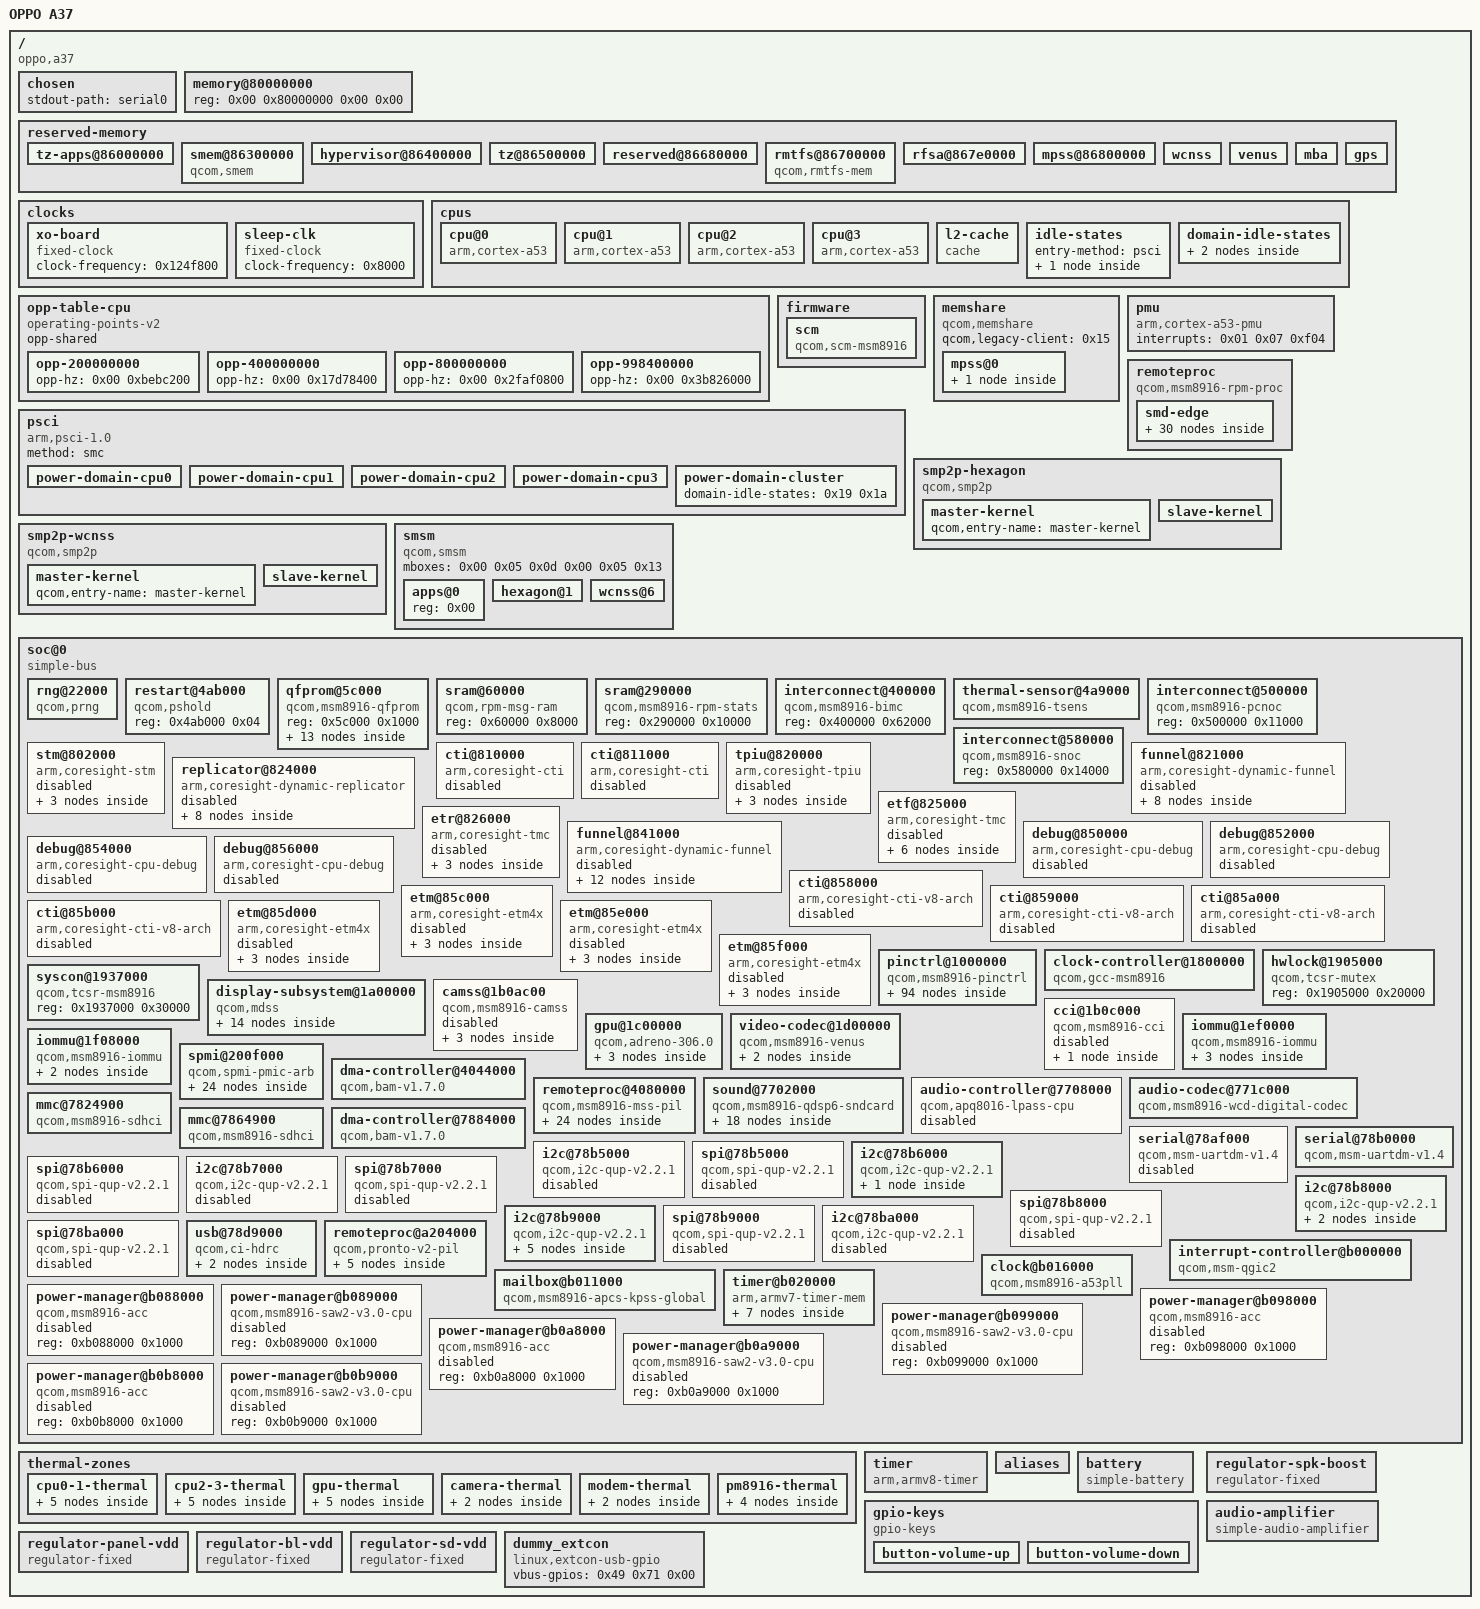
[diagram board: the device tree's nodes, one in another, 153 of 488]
/dts-v1/;

/ {
	interrupt-parent = <0x01>;
	#address-cells = <0x02>;
	#size-cells = <0x02>;
	model = "OPPO A37";
	compatible = "oppo,a37", "qcom,msm8916";
	chassis-type = "handset";

	chosen {
		stdout-path = "serial0";
	};

	memory@80000000 {
		device_type = "memory";
		reg = <0x00 0x80000000 0x00 0x00>;
	};

	reserved-memory {
		#address-cells = <0x02>;
		#size-cells = <0x02>;
		ranges;

		tz-apps@86000000 {
			reg = <0x00 0x86000000 0x00 0x300000>;
			no-map;
		};

		smem@86300000 {
			compatible = "qcom,smem";
			reg = <0x00 0x86300000 0x00 0x100000>;
			no-map;
			hwlocks = <0x02 0x03>;
			qcom,rpm-msg-ram = <0x03>;
		};

		hypervisor@86400000 {
			reg = <0x00 0x86400000 0x00 0x100000>;
			no-map;
		};

		tz@86500000 {
			reg = <0x00 0x86500000 0x00 0x180000>;
			no-map;
		};

		reserved@86680000 {
			reg = <0x00 0x86680000 0x00 0x80000>;
			no-map;
		};

		rmtfs@86700000 {
			compatible = "qcom,rmtfs-mem";
			reg = <0x00 0x86700000 0x00 0xe0000>;
			no-map;
			qcom,client-id = <0x01>;
		};

		rfsa@867e0000 {
			reg = <0x00 0x867e0000 0x00 0x20000>;
			no-map;
		};

		mpss@86800000 {
			reg = <0x00 0x86800000 0x00 0x5500000>;
			no-map;
			status = "okay";
			phandle = <0x6a>;
		};

		wcnss {
			size = <0x00 0x600000>;
			alignment = <0x00 0x100000>;
			alloc-ranges = <0x00 0x86800000 0x00 0x8000000>;
			no-map;
			status = "okay";
			phandle = <0xa2>;
		};

		venus {
			size = <0x00 0x500000>;
			alignment = <0x00 0x100000>;
			alloc-ranges = <0x00 0x86800000 0x00 0x8000000>;
			no-map;
			status = "okay";
			phandle = <0x5b>;
		};

		mba {
			size = <0x00 0x100000>;
			alignment = <0x00 0x100000>;
			alloc-ranges = <0x00 0x86800000 0x00 0x8000000>;
			no-map;
			status = "okay";
			phandle = <0x69>;
		};

		gps {
			size = <0x00 0x200000>;
			alignment = <0x00 0x100000>;
			alloc-ranges = <0x00 0x86800000 0x00 0x8000000>;
			no-map;
			status = "okay";
			phandle = <0x16>;
		};
	};

	clocks {

		xo-board {
			compatible = "fixed-clock";
			#clock-cells = <0x00>;
			clock-frequency = <0x124f800>;
			phandle = <0x1b>;
		};

		sleep-clk {
			compatible = "fixed-clock";
			#clock-cells = <0x00>;
			clock-frequency = <0x8000>;
			phandle = <0x4a>;
		};
	};

	cpus {
		#address-cells = <0x01>;
		#size-cells = <0x00>;

		cpu@0 {
			device_type = "cpu";
			compatible = "arm,cortex-a53";
			reg = <0x00>;
			next-level-cache = <0x04>;
			enable-method = "psci";
			clocks = <0x05>;
			operating-points-v2 = <0x06>;
			#cooling-cells = <0x02>;
			power-domains = <0x07>;
			power-domain-names = "psci";
			qcom,acc = <0x08>;
			qcom,saw = <0x09>;
			phandle = <0x3d>;
		};

		cpu@1 {
			device_type = "cpu";
			compatible = "arm,cortex-a53";
			reg = <0x01>;
			next-level-cache = <0x04>;
			enable-method = "psci";
			clocks = <0x05>;
			operating-points-v2 = <0x06>;
			#cooling-cells = <0x02>;
			power-domains = <0x0a>;
			power-domain-names = "psci";
			qcom,acc = <0x0b>;
			qcom,saw = <0x0c>;
			phandle = <0x3e>;
		};

		cpu@2 {
			device_type = "cpu";
			compatible = "arm,cortex-a53";
			reg = <0x02>;
			next-level-cache = <0x04>;
			enable-method = "psci";
			clocks = <0x05>;
			operating-points-v2 = <0x06>;
			#cooling-cells = <0x02>;
			power-domains = <0x0d>;
			power-domain-names = "psci";
			qcom,acc = <0x0e>;
			qcom,saw = <0x0f>;
			phandle = <0x3f>;
		};

		cpu@3 {
			device_type = "cpu";
			compatible = "arm,cortex-a53";
			reg = <0x03>;
			next-level-cache = <0x04>;
			enable-method = "psci";
			clocks = <0x05>;
			operating-points-v2 = <0x06>;
			#cooling-cells = <0x02>;
			power-domains = <0x10>;
			power-domain-names = "psci";
			qcom,acc = <0x11>;
			qcom,saw = <0x12>;
			phandle = <0x40>;
		};

		l2-cache {
			compatible = "cache";
			cache-level = <0x02>;
			cache-unified;
			phandle = <0x04>;
		};

		idle-states {
			entry-method = "psci";

			cpu-sleep-0 {
				compatible = "arm,idle-state";
				idle-state-name = "standalone-power-collapse";
				arm,psci-suspend-param = <0x40000002>;
				entry-latency-us = <0x82>;
				exit-latency-us = <0x96>;
				min-residency-us = <0x7d0>;
				local-timer-stop;
				phandle = <0x18>;
			};
		};

		domain-idle-states {

			cluster-retention {
				compatible = "domain-idle-state";
				arm,psci-suspend-param = <0x41000012>;
				entry-latency-us = <0x1f4>;
				exit-latency-us = <0x1f4>;
				min-residency-us = <0x7d0>;
				phandle = <0x19>;
			};

			cluster-gdhs {
				compatible = "domain-idle-state";
				arm,psci-suspend-param = <0x41000032>;
				entry-latency-us = <0x7d0>;
				exit-latency-us = <0x7d0>;
				min-residency-us = <0x1770>;
				phandle = <0x1a>;
			};
		};
	};

	opp-table-cpu {
		compatible = "operating-points-v2";
		opp-shared;
		phandle = <0x06>;

		opp-200000000 {
			opp-hz = <0x00 0xbebc200>;
		};

		opp-400000000 {
			opp-hz = <0x00 0x17d78400>;
		};

		opp-800000000 {
			opp-hz = <0x00 0x2faf0800>;
		};

		opp-998400000 {
			opp-hz = <0x00 0x3b826000>;
		};
	};

	firmware {

		scm {
			compatible = "qcom,scm-msm8916", "qcom,scm";
			clocks = <0x13 0x68 0x13 0x67 0x13 0x66>;
			clock-names = "core", "bus", "iface";
			#reset-cells = <0x01>;
			qcom,dload-mode = <0x14 0x6100>;
			phandle = <0x67>;
		};
	};

	memshare {
		compatible = "qcom,memshare";
		qcom,legacy-client = <0x15>;
		status = "okay";
		#address-cells = <0x01>;
		#size-cells = <0x00>;

		mpss@0 {
			reg = <0x00>;
			qcom,qrtr-node = <0x00>;
			#address-cells = <0x01>;
			#size-cells = <0x00>;

			gps@0 {
				reg = <0x00>;
				memory-region = <0x16>;
				phandle = <0x15>;
			};
		};
	};

	pmu {
		compatible = "arm,cortex-a53-pmu";
		interrupts = <0x01 0x07 0xf04>;
	};

	psci {
		compatible = "arm,psci-1.0";
		method = "smc";

		power-domain-cpu0 {
			#power-domain-cells = <0x00>;
			power-domains = <0x17>;
			domain-idle-states = <0x18>;
			phandle = <0x07>;
		};

		power-domain-cpu1 {
			#power-domain-cells = <0x00>;
			power-domains = <0x17>;
			domain-idle-states = <0x18>;
			phandle = <0x0a>;
		};

		power-domain-cpu2 {
			#power-domain-cells = <0x00>;
			power-domains = <0x17>;
			domain-idle-states = <0x18>;
			phandle = <0x0d>;
		};

		power-domain-cpu3 {
			#power-domain-cells = <0x00>;
			power-domains = <0x17>;
			domain-idle-states = <0x18>;
			phandle = <0x10>;
		};

		power-domain-cluster {
			#power-domain-cells = <0x00>;
			domain-idle-states = <0x19 0x1a>;
			phandle = <0x17>;
		};
	};

	remoteproc {
		compatible = "qcom,msm8916-rpm-proc", "qcom,rpm-proc";

		smd-edge {
			interrupts = <0x00 0xa8 0x01>;
			mboxes = <0x05 0x00>;
			qcom,smd-edge = <0x0f>;

			rpm-requests {
				compatible = "qcom,rpm-msm8916", "qcom,smd-rpm";
				qcom,smd-channels = "rpm_requests";

				clock-controller {
					compatible = "qcom,rpmcc-msm8916", "qcom,rpmcc";
					#clock-cells = <0x01>;
					clocks = <0x1b>;
					clock-names = "xo";
					phandle = <0x2c>;
				};

				power-controller {
					compatible = "qcom,msm8916-rpmpd";
					#power-domain-cells = <0x01>;
					operating-points-v2 = <0x1c>;
					phandle = <0x65>;

					opp-table {
						compatible = "operating-points-v2";
						phandle = <0x1c>;

						opp1 {
							opp-level = <0x01>;
						};

						opp2 {
							opp-level = <0x02>;
						};

						opp3 {
							opp-level = <0x03>;
						};

						opp4 {
							opp-level = <0x04>;
						};

						opp5 {
							opp-level = <0x05>;
						};

						opp6 {
							opp-level = <0x06>;
						};
					};
				};

				regulators {
					compatible = "qcom,rpm-pm8916-regulators";
					vdd_l1_l2_l3-supply = <0x1d>;
					vdd_l4_l5_l6-supply = <0x1e>;
					vdd_l7-supply = <0x1e>;

					s3 {
						regulator-min-microvolt = <0x1312d0>;
						regulator-max-microvolt = <0x149970>;
						regulator-always-on;
						phandle = <0x1d>;
					};

					s4 {
						regulator-min-microvolt = <0x1c3a90>;
						regulator-max-microvolt = <0x20ce70>;
						regulator-always-on;
						phandle = <0x1e>;
					};

					l1 {
					};

					l2 {
						regulator-min-microvolt = <0x124f80>;
						regulator-max-microvolt = <0x124f80>;
						regulator-always-on;
						phandle = <0x4f>;
					};

					l4 {
					};

					l5 {
						regulator-min-microvolt = <0x1b7740>;
						regulator-max-microvolt = <0x1b7740>;
						regulator-always-on;
						phandle = <0x62>;
					};

					l6 {
						regulator-min-microvolt = <0x1b7740>;
						regulator-max-microvolt = <0x1b7740>;
						phandle = <0x50>;
					};

					l7 {
						regulator-min-microvolt = <0x1b7740>;
						regulator-max-microvolt = <0x1b7740>;
						regulator-always-on;
						phandle = <0x68>;
					};

					l8 {
						regulator-min-microvolt = <0x1b7740>;
						regulator-max-microvolt = <0x2d0370>;
						regulator-always-on;
						regulator-boot-on;
						phandle = <0x78>;
					};

					l9 {
						regulator-min-microvolt = <0x325aa0>;
						regulator-max-microvolt = <0x325aa0>;
						regulator-always-on;
						regulator-boot-on;
						phandle = <0xa6>;
					};

					l10 {
					};

					l11 {
						regulator-min-microvolt = <0x2d0370>;
						regulator-max-microvolt = <0x2d0370>;
						regulator-allow-set-load;
						regulator-system-load = <0x30d40>;
					};

					l12 {
						regulator-min-microvolt = <0x1b7740>;
						regulator-max-microvolt = <0x2d0370>;
						phandle = <0x7d>;
					};

					l13 {
						regulator-min-microvolt = <0x2eebb8>;
						regulator-max-microvolt = <0x2eebb8>;
						phandle = <0x63>;
					};

					l14 {
						regulator-min-microvolt = <0x1b7740>;
						regulator-max-microvolt = <0x2d0370>;
						regulator-always-on;
						regulator-boot-on;
					};

					l15 {
						regulator-min-microvolt = <0x1b7740>;
						regulator-max-microvolt = <0x2d0370>;
						regulator-always-on;
						regulator-boot-on;
					};

					l16 {
					};

					l17 {
						regulator-min-microvolt = <0x2b7cd0>;
						regulator-max-microvolt = <0x2b7cd0>;
						phandle = <0x89>;
					};

					l18 {
					};
				};
			};
		};
	};

	smp2p-hexagon {
		compatible = "qcom,smp2p";
		qcom,smem = <0x1b3 0x1ac>;
		interrupts = <0x00 0x1b 0x01>;
		mboxes = <0x05 0x0e>;
		qcom,local-pid = <0x00>;
		qcom,remote-pid = <0x01>;

		master-kernel {
			qcom,entry-name = "master-kernel";
			#qcom,smem-state-cells = <0x01>;
			phandle = <0x66>;
		};

		slave-kernel {
			qcom,entry-name = "slave-kernel";
			interrupt-controller;
			#interrupt-cells = <0x02>;
			phandle = <0x64>;
		};
	};

	smp2p-wcnss {
		compatible = "qcom,smp2p";
		qcom,smem = <0x1c3 0x1af>;
		interrupts = <0x00 0x8f 0x01>;
		mboxes = <0x05 0x12>;
		qcom,local-pid = <0x00>;
		qcom,remote-pid = <0x04>;

		master-kernel {
			qcom,entry-name = "master-kernel";
			#qcom,smem-state-cells = <0x01>;
			phandle = <0xa4>;
		};

		slave-kernel {
			qcom,entry-name = "slave-kernel";
			interrupt-controller;
			#interrupt-cells = <0x02>;
			phandle = <0xa3>;
		};
	};

	smsm {
		compatible = "qcom,smsm";
		#address-cells = <0x01>;
		#size-cells = <0x00>;
		mboxes = <0x00 0x05 0x0d 0x00 0x05 0x13>;

		apps@0 {
			reg = <0x00>;
			#qcom,smem-state-cells = <0x01>;
			phandle = <0x6c>;
		};

		hexagon@1 {
			reg = <0x01>;
			interrupts = <0x00 0x1a 0x01>;
			interrupt-controller;
			#interrupt-cells = <0x02>;
			phandle = <0x6b>;
		};

		wcnss@6 {
			reg = <0x06>;
			interrupts = <0x00 0x90 0x01>;
			interrupt-controller;
			#interrupt-cells = <0x02>;
		};
	};

	soc@0 {
		#address-cells = <0x01>;
		#size-cells = <0x01>;
		ranges = <0x00 0x00 0x00 0xffffffff>;
		compatible = "simple-bus";

		rng@22000 {
			compatible = "qcom,prng";
			reg = <0x22000 0x200>;
			clocks = <0x13 0x79>;
			clock-names = "core";
		};

		restart@4ab000 {
			compatible = "qcom,pshold";
			reg = <0x4ab000 0x04>;
		};

		qfprom@5c000 {
			compatible = "qcom,msm8916-qfprom", "qcom,qfprom";
			reg = <0x5c000 0x1000>;
			#address-cells = <0x01>;
			#size-cells = <0x01>;

			base1@d0 {
				reg = <0xd0 0x01>;
				bits = <0x00 0x07>;
				phandle = <0x20>;
			};

			s0-p1@d0 {
				reg = <0xd0 0x02>;
				bits = <0x07 0x05>;
				phandle = <0x22>;
			};

			s0-p2@d1 {
				reg = <0xd1 0x02>;
				bits = <0x04 0x05>;
				phandle = <0x23>;
			};

			s1-p1@d2 {
				reg = <0xd2 0x01>;
				bits = <0x01 0x05>;
				phandle = <0x24>;
			};

			s1-p2@d2 {
				reg = <0xd2 0x02>;
				bits = <0x06 0x05>;
				phandle = <0x25>;
			};

			s2-p1@d3 {
				reg = <0xd3 0x01>;
				bits = <0x03 0x05>;
				phandle = <0x26>;
			};

			s2-p2@d4 {
				reg = <0xd4 0x01>;
				bits = <0x00 0x05>;
				phandle = <0x27>;
			};

			s4-p1@d4 {
				reg = <0xd4 0x02>;
				bits = <0x05 0x05>;
				phandle = <0x28>;
			};

			s4-p2@d5 {
				reg = <0xd5 0x01>;
				bits = <0x02 0x05>;
				phandle = <0x29>;
			};

			s5-p1@d5 {
				reg = <0xd5 0x02>;
				bits = <0x07 0x05>;
				phandle = <0x2a>;
			};

			s5-p2@d6 {
				reg = <0xd6 0x02>;
				bits = <0x04 0x05>;
				phandle = <0x2b>;
			};

			base2@d7 {
				reg = <0xd7 0x01>;
				bits = <0x01 0x07>;
				phandle = <0x21>;
			};

			mode@ef {
				reg = <0xef 0x01>;
				bits = <0x05 0x03>;
				phandle = <0x1f>;
			};
		};

		sram@60000 {
			compatible = "qcom,rpm-msg-ram";
			reg = <0x60000 0x8000>;
			phandle = <0x03>;
		};

		sram@290000 {
			compatible = "qcom,msm8916-rpm-stats";
			reg = <0x290000 0x10000>;
		};

		interconnect@400000 {
			compatible = "qcom,msm8916-bimc";
			reg = <0x400000 0x62000>;
			#interconnect-cells = <0x01>;
		};

		thermal-sensor@4a9000 {
			compatible = "qcom,msm8916-tsens", "qcom,tsens-v0_1";
			reg = <0x4a9000 0x1000 0x4a8000 0x1000>;
			nvmem-cells = <0x1f 0x20 0x21 0x22 0x23 0x24 0x25 0x26 0x27 0x28 0x29 0x2a 0x2b>;
			nvmem-cell-names = "mode", "base1", "base2", "s0_p1", "s0_p2", "s1_p1", "s1_p2", "s2_p1", "s2_p2", "s4_p1", "s4_p2", "s5_p1", "s5_p2";
			#qcom,sensors = <0x05>;
			interrupts = <0x00 0xb8 0x04>;
			interrupt-names = "uplow";
			#thermal-sensor-cells = <0x01>;
			phandle = <0xa9>;
		};

		interconnect@500000 {
			compatible = "qcom,msm8916-pcnoc";
			reg = <0x500000 0x11000>;
			#interconnect-cells = <0x01>;
		};

		interconnect@580000 {
			compatible = "qcom,msm8916-snoc";
			reg = <0x580000 0x14000>;
			#interconnect-cells = <0x01>;
		};

		stm@802000 {
			compatible = "arm,coresight-stm", "arm,primecell";
			reg = <0x802000 0x1000 0x9280000 0x180000>;
			reg-names = "stm-base", "stm-stimulus-base";
			clocks = <0x2c 0x08 0x2c 0x09>;
			clock-names = "apb_pclk", "atclk";
			status = "disabled";

			out-ports {

				port {

					endpoint {
						remote-endpoint = <0x2d>;
						phandle = <0x30>;
					};
				};
			};
		};

		cti@810000 {
			compatible = "arm,coresight-cti", "arm,primecell";
			reg = <0x810000 0x1000>;
			clocks = <0x2c 0x08>;
			clock-names = "apb_pclk";
			status = "disabled";
		};

		cti@811000 {
			compatible = "arm,coresight-cti", "arm,primecell";
			reg = <0x811000 0x1000>;
			clocks = <0x2c 0x08>;
			clock-names = "apb_pclk";
			status = "disabled";
		};

		tpiu@820000 {
			compatible = "arm,coresight-tpiu", "arm,primecell";
			reg = <0x820000 0x1000>;
			clocks = <0x2c 0x08 0x2c 0x09>;
			clock-names = "apb_pclk", "atclk";
			status = "disabled";

			in-ports {

				port {

					endpoint {
						remote-endpoint = <0x2e>;
						phandle = <0x33>;
					};
				};
			};
		};

		funnel@821000 {
			compatible = "arm,coresight-dynamic-funnel", "arm,primecell";
			reg = <0x821000 0x1000>;
			clocks = <0x2c 0x08 0x2c 0x09>;
			clock-names = "apb_pclk", "atclk";
			status = "disabled";

			in-ports {
				#address-cells = <0x01>;
				#size-cells = <0x00>;

				port@4 {
					reg = <0x04>;

					endpoint {
						remote-endpoint = <0x2f>;
						phandle = <0x3c>;
					};
				};

				port@7 {
					reg = <0x07>;

					endpoint {
						remote-endpoint = <0x30>;
						phandle = <0x2d>;
					};
				};
			};

			out-ports {

				port {

					endpoint {
						remote-endpoint = <0x31>;
						phandle = <0x35>;
					};
				};
			};
		};

		replicator@824000 {
			compatible = "arm,coresight-dynamic-replicator", "arm,primecell";
			reg = <0x824000 0x1000>;
			clocks = <0x2c 0x08 0x2c 0x09>;
			clock-names = "apb_pclk", "atclk";
			status = "disabled";

			out-ports {
				#address-cells = <0x01>;
				#size-cells = <0x00>;

				port@0 {
					reg = <0x00>;

					endpoint {
						remote-endpoint = <0x32>;
						phandle = <0x37>;
					};
				};

				port@1 {
					reg = <0x01>;

					endpoint {
						remote-endpoint = <0x33>;
						phandle = <0x2e>;
					};
				};
			};

			in-ports {

				port {

					endpoint {
						remote-endpoint = <0x34>;
						phandle = <0x36>;
					};
				};
			};
		};

		etf@825000 {
			compatible = "arm,coresight-tmc", "arm,primecell";
			reg = <0x825000 0x1000>;
			clocks = <0x2c 0x08 0x2c 0x09>;
			clock-names = "apb_pclk", "atclk";
			status = "disabled";

			in-ports {

				port {

					endpoint {
						remote-endpoint = <0x35>;
						phandle = <0x31>;
					};
				};
			};

			out-ports {

				port {

					endpoint {
						remote-endpoint = <0x36>;
						phandle = <0x34>;
					};
				};
			};
		};

		etr@826000 {
			compatible = "arm,coresight-tmc", "arm,primecell";
			reg = <0x826000 0x1000>;
			clocks = <0x2c 0x08 0x2c 0x09>;
			clock-names = "apb_pclk", "atclk";
			status = "disabled";

			in-ports {

				port {

					endpoint {
						remote-endpoint = <0x37>;
						phandle = <0x32>;
					};
				};
			};
		};

		funnel@841000 {
			compatible = "arm,coresight-dynamic-funnel", "arm,primecell";
			reg = <0x841000 0x1000>;
			clocks = <0x2c 0x08 0x2c 0x09>;
			clock-names = "apb_pclk", "atclk";
			status = "disabled";

			in-ports {
				#address-cells = <0x01>;
				#size-cells = <0x00>;

				port@0 {
					reg = <0x00>;

					endpoint {
						remote-endpoint = <0x38>;
						phandle = <0x45>;
					};
				};

				port@1 {
					reg = <0x01>;

					endpoint {
						remote-endpoint = <0x39>;
						phandle = <0x46>;
					};
				};

				port@2 {
					reg = <0x02>;

					endpoint {
						remote-endpoint = <0x3a>;
						phandle = <0x47>;
					};
				};

				port@3 {
					reg = <0x03>;

					endpoint {
						remote-endpoint = <0x3b>;
						phandle = <0x48>;
					};
				};
			};

			out-ports {

				port {

					endpoint {
						remote-endpoint = <0x3c>;
						phandle = <0x2f>;
					};
				};
			};
		};

		debug@850000 {
			compatible = "arm,coresight-cpu-debug", "arm,primecell";
			reg = <0x850000 0x1000>;
			clocks = <0x2c 0x08>;
			clock-names = "apb_pclk";
			cpu = <0x3d>;
			status = "disabled";
		};

		debug@852000 {
			compatible = "arm,coresight-cpu-debug", "arm,primecell";
			reg = <0x852000 0x1000>;
			clocks = <0x2c 0x08>;
			clock-names = "apb_pclk";
			cpu = <0x3e>;
			status = "disabled";
		};

		debug@854000 {
			compatible = "arm,coresight-cpu-debug", "arm,primecell";
			reg = <0x854000 0x1000>;
			clocks = <0x2c 0x08>;
			clock-names = "apb_pclk";
			cpu = <0x3f>;
			status = "disabled";
		};

		debug@856000 {
			compatible = "arm,coresight-cpu-debug", "arm,primecell";
			reg = <0x856000 0x1000>;
			clocks = <0x2c 0x08>;
			clock-names = "apb_pclk";
			cpu = <0x40>;
			status = "disabled";
		};

		cti@858000 {
			compatible = "arm,coresight-cti-v8-arch", "arm,coresight-cti", "arm,primecell";
			reg = <0x858000 0x1000>;
			clocks = <0x2c 0x08>;
			clock-names = "apb_pclk";
			cpu = <0x3d>;
			arm,cs-dev-assoc = <0x41>;
			status = "disabled";
		};

		cti@859000 {
			compatible = "arm,coresight-cti-v8-arch", "arm,coresight-cti", "arm,primecell";
			reg = <0x859000 0x1000>;
			clocks = <0x2c 0x08>;
			clock-names = "apb_pclk";
			cpu = <0x3e>;
			arm,cs-dev-assoc = <0x42>;
			status = "disabled";
		};

		cti@85a000 {
			compatible = "arm,coresight-cti-v8-arch", "arm,coresight-cti", "arm,primecell";
			reg = <0x85a000 0x1000>;
			clocks = <0x2c 0x08>;
			clock-names = "apb_pclk";
			cpu = <0x3f>;
			arm,cs-dev-assoc = <0x43>;
			status = "disabled";
		};

		cti@85b000 {
			compatible = "arm,coresight-cti-v8-arch", "arm,coresight-cti", "arm,primecell";
			reg = <0x85b000 0x1000>;
			clocks = <0x2c 0x08>;
			clock-names = "apb_pclk";
			cpu = <0x40>;
			arm,cs-dev-assoc = <0x44>;
			status = "disabled";
		};

		etm@85c000 {
			compatible = "arm,coresight-etm4x", "arm,primecell";
			reg = <0x85c000 0x1000>;
			clocks = <0x2c 0x08 0x2c 0x09>;
			clock-names = "apb_pclk", "atclk";
			arm,coresight-loses-context-with-cpu;
			cpu = <0x3d>;
			status = "disabled";
			phandle = <0x41>;

			out-ports {

				port {

					endpoint {
						remote-endpoint = <0x45>;
						phandle = <0x38>;
					};
				};
			};
		};

		etm@85d000 {
			compatible = "arm,coresight-etm4x", "arm,primecell";
			reg = <0x85d000 0x1000>;
			clocks = <0x2c 0x08 0x2c 0x09>;
			clock-names = "apb_pclk", "atclk";
			arm,coresight-loses-context-with-cpu;
			cpu = <0x3e>;
			status = "disabled";
			phandle = <0x42>;

			out-ports {

				port {

					endpoint {
						remote-endpoint = <0x46>;
						phandle = <0x39>;
					};
				};
			};
		};

		etm@85e000 {
			compatible = "arm,coresight-etm4x", "arm,primecell";
			reg = <0x85e000 0x1000>;
			clocks = <0x2c 0x08 0x2c 0x09>;
			clock-names = "apb_pclk", "atclk";
			arm,coresight-loses-context-with-cpu;
			cpu = <0x3f>;
			status = "disabled";
			phandle = <0x43>;

			out-ports {

				port {

					endpoint {
						remote-endpoint = <0x47>;
						phandle = <0x3a>;
					};
				};
			};
		};

		etm@85f000 {
			compatible = "arm,coresight-etm4x", "arm,primecell";
			reg = <0x85f000 0x1000>;
			clocks = <0x2c 0x08 0x2c 0x09>;
			clock-names = "apb_pclk", "atclk";
			arm,coresight-loses-context-with-cpu;
			cpu = <0x40>;
			status = "disabled";
			phandle = <0x44>;

			out-ports {

				port {

					endpoint {
						remote-endpoint = <0x48>;
						phandle = <0x3b>;
					};
				};
			};
		};

		pinctrl@1000000 {
			compatible = "qcom,msm8916-pinctrl";
			reg = <0x1000000 0x300000>;
			interrupts = <0x00 0xd0 0x04>;
			gpio-controller;
			gpio-ranges = <0x49 0x00 0x00 0x7a>;
			#gpio-cells = <0x02>;
			interrupt-controller;
			#interrupt-cells = <0x02>;
			phandle = <0x49>;

			blsp-i2c1-default-state {
				pins = "gpio2", "gpio3";
				function = "blsp_i2c1";
				drive-strength = <0x02>;
				bias-disable;
				phandle = <0x83>;
			};

			blsp-i2c1-sleep-state {
				pins = "gpio2", "gpio3";
				function = "gpio";
				drive-strength = <0x02>;
				bias-disable;
				phandle = <0x84>;
			};

			blsp-i2c2-default-state {
				pins = "gpio6", "gpio7";
				function = "blsp_i2c2";
				drive-strength = <0x02>;
				bias-disable;
				phandle = <0x87>;
			};

			blsp-i2c2-sleep-state {
				pins = "gpio6", "gpio7";
				function = "gpio";
				drive-strength = <0x02>;
				bias-disable;
				phandle = <0x88>;
			};

			blsp-i2c3-default-state {
				pins = "gpio10", "gpio11";
				function = "blsp_i2c3";
				drive-strength = <0x02>;
				bias-disable;
				phandle = <0x8c>;
			};

			blsp-i2c3-sleep-state {
				pins = "gpio10", "gpio11";
				function = "gpio";
				drive-strength = <0x02>;
				bias-disable;
				phandle = <0x8d>;
			};

			blsp-i2c4-default-state {
				pins = "gpio14", "gpio15";
				function = "blsp_i2c4";
				drive-strength = <0x02>;
				bias-disable;
				phandle = <0x90>;
			};

			blsp-i2c4-sleep-state {
				pins = "gpio14", "gpio15";
				function = "gpio";
				drive-strength = <0x02>;
				bias-disable;
				phandle = <0x91>;
			};

			blsp-i2c5-default-state {
				pins = "gpio18", "gpio19";
				function = "blsp_i2c5";
				drive-strength = <0x02>;
				bias-disable;
				phandle = <0x95>;
			};

			blsp-i2c5-sleep-state {
				pins = "gpio18", "gpio19";
				function = "gpio";
				drive-strength = <0x02>;
				bias-disable;
				phandle = <0x96>;
			};

			blsp-i2c6-default-state {
				pins = "gpio22", "gpio23";
				function = "blsp_i2c6";
				drive-strength = <0x02>;
				bias-disable;
				phandle = <0x9b>;
			};

			blsp-i2c6-sleep-state {
				pins = "gpio22", "gpio23";
				function = "gpio";
				drive-strength = <0x02>;
				bias-disable;
				phandle = <0x9c>;
			};

			blsp-spi1-default-state {
				phandle = <0x85>;

				spi-pins {
					pins = "gpio0", "gpio1", "gpio3";
					function = "blsp_spi1";
					drive-strength = <0x0c>;
					bias-disable;
				};

				cs-pins {
					pins = "gpio2";
					function = "gpio";
					drive-strength = <0x10>;
					bias-disable;
					output-high;
				};
			};

			blsp-spi1-sleep-state {
				pins = "gpio0", "gpio1", "gpio2", "gpio3";
				function = "gpio";
				drive-strength = <0x02>;
				bias-pull-down;
				phandle = <0x86>;
			};

			blsp-spi2-default-state {
				phandle = <0x8a>;

				spi-pins {
					pins = "gpio4", "gpio5", "gpio7";
					function = "blsp_spi2";
					drive-strength = <0x0c>;
					bias-disable;
				};

				cs-pins {
					pins = "gpio6";
					function = "gpio";
					drive-strength = <0x10>;
					bias-disable;
					output-high;
				};
			};

			blsp-spi2-sleep-state {
				pins = "gpio4", "gpio5", "gpio6", "gpio7";
				function = "gpio";
				drive-strength = <0x02>;
				bias-pull-down;
				phandle = <0x8b>;
			};

			blsp-spi3-default-state {
				phandle = <0x8e>;

				spi-pins {
					pins = "gpio8", "gpio9", "gpio11";
					function = "blsp_spi3";
					drive-strength = <0x0c>;
					bias-disable;
				};

				cs-pins {
					pins = "gpio10";
					function = "gpio";
					drive-strength = <0x10>;
					bias-disable;
					output-high;
				};
			};

			blsp-spi3-sleep-state {
				pins = "gpio8", "gpio9", "gpio10", "gpio11";
				function = "gpio";
				drive-strength = <0x02>;
				bias-pull-down;
				phandle = <0x8f>;
			};

			blsp-spi4-default-state {
				phandle = <0x93>;

				spi-pins {
					pins = "gpio12", "gpio13", "gpio15";
					function = "blsp_spi4";
					drive-strength = <0x0c>;
					bias-disable;
				};

				cs-pins {
					pins = "gpio14";
					function = "gpio";
					drive-strength = <0x10>;
					bias-disable;
					output-high;
				};
			};

			blsp-spi4-sleep-state {
				pins = "gpio12", "gpio13", "gpio14", "gpio15";
				function = "gpio";
				drive-strength = <0x02>;
				bias-pull-down;
				phandle = <0x94>;
			};

			blsp-spi5-default-state {
				phandle = <0x99>;

				spi-pins {
					pins = "gpio16", "gpio17", "gpio19";
					function = "blsp_spi5";
					drive-strength = <0x0c>;
					bias-disable;
				};

				cs-pins {
					pins = "gpio18";
					function = "gpio";
					drive-strength = <0x10>;
					bias-disable;
					output-high;
				};
			};

			blsp-spi5-sleep-state {
				pins = "gpio16", "gpio17", "gpio18", "gpio19";
				function = "gpio";
				drive-strength = <0x02>;
				bias-pull-down;
				phandle = <0x9a>;
			};

			blsp-spi6-default-state {
				phandle = <0x9d>;

				spi-pins {
					pins = "gpio20", "gpio21", "gpio23";
					function = "blsp_spi6";
					drive-strength = <0x0c>;
					bias-disable;
				};

				cs-pins {
					pins = "gpio22";
					function = "gpio";
					drive-strength = <0x10>;
					bias-disable;
					output-high;
				};
			};

			blsp-spi6-sleep-state {
				pins = "gpio20", "gpio21", "gpio22", "gpio23";
				function = "gpio";
				drive-strength = <0x02>;
				bias-pull-down;
				phandle = <0x9e>;
			};

			blsp-uart1-default-state {
				pins = "gpio0", "gpio1", "gpio2", "gpio3";
				function = "blsp_uart1";
				drive-strength = <0x10>;
				bias-disable;
				phandle = <0x7f>;
			};

			blsp-uart1-sleep-state {
				pins = "gpio0", "gpio1", "gpio2", "gpio3";
				function = "gpio";
				drive-strength = <0x02>;
				bias-pull-down;
				phandle = <0x80>;
			};

			blsp-uart2-default-state {
				pins = "gpio4", "gpio5";
				function = "blsp_uart2";
				drive-strength = <0x10>;
				bias-disable;
				phandle = <0x81>;
			};

			blsp-uart2-sleep-state {
				pins = "gpio4", "gpio5";
				function = "gpio";
				drive-strength = <0x02>;
				bias-pull-down;
				phandle = <0x82>;
			};

			camera-front-default-state {

				pwdn-pins {
					pins = "gpio33";
					function = "gpio";
					drive-strength = <0x10>;
					bias-disable;
				};

				rst-pins {
					pins = "gpio28";
					function = "gpio";
					drive-strength = <0x10>;
					bias-disable;
				};

				mclk1-pins {
					pins = "gpio27";
					function = "cam_mclk1";
					drive-strength = <0x10>;
					bias-disable;
				};
			};

			camera-rear-default-state {

				pwdn-pins {
					pins = "gpio34";
					function = "gpio";
					drive-strength = <0x10>;
					bias-disable;
				};

				rst-pins {
					pins = "gpio35";
					function = "gpio";
					drive-strength = <0x10>;
					bias-disable;
				};

				mclk0-pins {
					pins = "gpio26";
					function = "cam_mclk0";
					drive-strength = <0x10>;
					bias-disable;
				};
			};

			cci0-default-state {
				pins = "gpio29", "gpio30";
				function = "cci_i2c";
				drive-strength = <0x10>;
				bias-disable;
				phandle = <0x58>;
			};

			cdc-dmic-default-state {

				clk-pins {
					pins = "gpio0";
					function = "dmic0_clk";
					drive-strength = <0x08>;
				};

				data-pins {
					pins = "gpio1";
					function = "dmic0_data";
					drive-strength = <0x08>;
				};
			};

			cdc-dmic-sleep-state {

				clk-pins {
					pins = "gpio0";
					function = "dmic0_clk";
					drive-strength = <0x02>;
					bias-disable;
				};

				data-pins {
					pins = "gpio1";
					function = "dmic0_data";
					drive-strength = <0x02>;
					bias-disable;
				};
			};

			cdc-pdm-default-state {
				pins = "gpio63", "gpio64", "gpio65", "gpio66", "gpio67", "gpio68";
				function = "cdc_pdm0";
				drive-strength = <0x08>;
				bias-disable;
				phandle = <0x6e>;
			};

			cdc-pdm-sleep-state {
				pins = "gpio63", "gpio64", "gpio65", "gpio66", "gpio67", "gpio68";
				function = "cdc_pdm0";
				drive-strength = <0x02>;
				bias-pull-down;
				phandle = <0x6f>;
			};

			mi2s-pri-default-state {
				pins = "gpio113", "gpio114", "gpio115", "gpio116";
				function = "pri_mi2s";
				drive-strength = <0x08>;
				bias-disable;
			};

			mi2s-pri-sleep-state {
				pins = "gpio113", "gpio114", "gpio115", "gpio116";
				function = "pri_mi2s";
				drive-strength = <0x02>;
				bias-disable;
			};

			mi2s-pri-mclk-default-state {
				pins = "gpio116";
				function = "pri_mi2s";
				drive-strength = <0x08>;
				bias-disable;
			};

			mi2s-pri-mclk-sleep-state {
				pins = "gpio116";
				function = "pri_mi2s";
				drive-strength = <0x02>;
				bias-disable;
			};

			mi2s-pri-ws-default-state {
				pins = "gpio110";
				function = "pri_mi2s_ws";
				drive-strength = <0x08>;
				bias-disable;
			};

			mi2s-pri-ws-sleep-state {
				pins = "gpio110";
				function = "pri_mi2s_ws";
				drive-strength = <0x02>;
				bias-disable;
			};

			mi2s-sec-default-state {
				pins = "gpio112", "gpio117", "gpio118", "gpio119";
				function = "sec_mi2s";
				drive-strength = <0x08>;
				bias-disable;
			};

			mi2s-sec-sleep-state {
				pins = "gpio112", "gpio117", "gpio118", "gpio119";
				function = "sec_mi2s";
				drive-strength = <0x02>;
				bias-disable;
			};

			sdc1-default-state {
				phandle = <0x76>;

				clk-pins {
					pins = "sdc1_clk";
					bias-disable;
					drive-strength = <0x10>;
				};

				cmd-pins {
					pins = "sdc1_cmd";
					bias-pull-up;
					drive-strength = <0x0a>;
				};

				data-pins {
					pins = "sdc1_data";
					bias-pull-up;
					drive-strength = <0x0a>;
				};
			};

			sdc1-sleep-state {
				phandle = <0x77>;

				clk-pins {
					pins = "sdc1_clk";
					bias-disable;
					drive-strength = <0x02>;
				};

				cmd-pins {
					pins = "sdc1_cmd";
					bias-pull-up;
					drive-strength = <0x02>;
				};

				data-pins {
					pins = "sdc1_data";
					bias-pull-up;
					drive-strength = <0x02>;
				};
			};

			sdc2-default-state {
				phandle = <0x79>;

				clk-pins {
					pins = "sdc2_clk";
					bias-disable;
					drive-strength = <0x10>;
				};

				cmd-pins {
					pins = "sdc2_cmd";
					bias-pull-up;
					drive-strength = <0x0a>;
				};

				data-pins {
					pins = "sdc2_data";
					bias-pull-up;
					drive-strength = <0x0a>;
				};
			};

			sdc2-sleep-state {
				phandle = <0x7b>;

				clk-pins {
					pins = "sdc2_clk";
					bias-disable;
					drive-strength = <0x02>;
				};

				cmd-pins {
					pins = "sdc2_cmd";
					bias-pull-up;
					drive-strength = <0x02>;
				};

				data-pins {
					pins = "sdc2_data";
					bias-pull-up;
					drive-strength = <0x02>;
				};
			};

			wcss-wlan-default-state {
				pins = "gpio40", "gpio41", "gpio42", "gpio43", "gpio44";
				function = "wcss_wlan";
				drive-strength = <0x06>;
				bias-pull-up;
				phandle = <0xa5>;
			};

			accel-int-default-state {
				pins = "gpio34";
				function = "gpio";
				drive-strength = <0x06>;
				bias-pull-down;
			};

			bl-en-default-state {
				pins = "gpio98";
				function = "gpio";
				drive-strength = <0x02>;
				bias-disable;
				phandle = <0xb1>;
			};

			bl-hwen-default-state {
				pins = "gpio69";
				function = "gpio";
				drive-strength = <0x02>;
				bias-disable;
				phandle = <0x98>;
			};

			chg-int-default-state {
				pins = "gpio62";
				function = "gpio";
				drive-strength = <0x02>;
				bias-pull-up;
				phandle = <0x92>;
			};

			gpio-keys-default-state {
				pins = "gpio107", "gpio108";
				function = "gpio";
				drive-strength = <0x02>;
				bias-pull-up;
				phandle = <0xaf>;
			};

			mdss-default-state {
				pins = "gpio25";
				function = "gpio";
				drive-strength = <0x08>;
				bias-disable;
				phandle = <0x51>;
			};

			mdss-sleep-state {
				pins = "gpio25";
				function = "gpio";
				drive-strength = <0x02>;
				bias-pull-down;
				phandle = <0x52>;
			};

			panel-vdd-default-state {
				pins = "gpio97";
				function = "gpio";
				drive-strength = <0x02>;
				bias-disable;
				phandle = <0xb0>;
			};

			prox-int-default-state {
				pins = "gpio9";
				function = "gpio";
				drive-strength = <0x02>;
				bias-pull-up;
			};

			sd-vdd-en-default-state {
				pins = "gpio116";
				function = "gpio";
				drive-strength = <0x02>;
				bias-disable;
				phandle = <0xb2>;
			};

			sdc2-cd-default-state {
				pins = "gpio38";
				function = "gpio";
				drive-strength = <0x02>;
				bias-pull-up;
				phandle = <0x7a>;
			};

			tp-int-default-state {
				pins = "gpio13";
				function = "gpio";
				drive-strength = <0x02>;
				bias-disable;
				phandle = <0x97>;
			};
		};

		clock-controller@1800000 {
			compatible = "qcom,gcc-msm8916";
			#clock-cells = <0x01>;
			#reset-cells = <0x01>;
			#power-domain-cells = <0x01>;
			reg = <0x1800000 0x80000>;
			clocks = <0x1b 0x4a 0x4b 0x01 0x4b 0x00 0x00 0x00 0x00>;
			clock-names = "xo", "sleep_clk", "dsi0pll", "dsi0pllbyte", "ext_mclk", "ext_pri_i2s", "ext_sec_i2s";
			phandle = <0x13>;
		};

		hwlock@1905000 {
			compatible = "qcom,tcsr-mutex";
			reg = <0x1905000 0x20000>;
			#hwlock-cells = <0x01>;
			phandle = <0x02>;
		};

		syscon@1937000 {
			compatible = "qcom,tcsr-msm8916", "syscon";
			reg = <0x1937000 0x30000>;
			phandle = <0x14>;
		};

		display-subsystem@1a00000 {
			status = "okay";
			compatible = "qcom,mdss";
			reg = <0x1a00000 0x1000 0x1ac8000 0x3000>;
			reg-names = "mdss_phys", "vbif_phys";
			power-domains = <0x13 0x02>;
			clocks = <0x13 0x6d 0x13 0x6e 0x13 0x73>;
			clock-names = "iface", "bus", "vsync";
			interrupts = <0x00 0x48 0x04>;
			interrupt-controller;
			#interrupt-cells = <0x01>;
			#address-cells = <0x01>;
			#size-cells = <0x01>;
			ranges;
			phandle = <0x4c>;

			display-controller@1a01000 {
				compatible = "qcom,msm8916-mdp5", "qcom,mdp5";
				reg = <0x1a01000 0x89000>;
				reg-names = "mdp_phys";
				interrupt-parent = <0x4c>;
				interrupts = <0x00>;
				clocks = <0x13 0x6d 0x13 0x6e 0x13 0x71 0x13 0x73>;
				clock-names = "iface", "bus", "core", "vsync";
				iommus = <0x4d 0x04>;

				ports {
					#address-cells = <0x01>;
					#size-cells = <0x00>;

					port@0 {
						reg = <0x00>;

						endpoint {
							remote-endpoint = <0x4e>;
							phandle = <0x53>;
						};
					};
				};
			};

			dsi@1a98000 {
				compatible = "qcom,msm8916-dsi-ctrl", "qcom,mdss-dsi-ctrl";
				reg = <0x1a98000 0x25c>;
				reg-names = "dsi_ctrl";
				interrupt-parent = <0x4c>;
				interrupts = <0x04>;
				assigned-clocks = <0x13 0x2b 0x13 0x2e>;
				assigned-clock-parents = <0x4b 0x00 0x4b 0x01>;
				clocks = <0x13 0x71 0x13 0x6d 0x13 0x6e 0x13 0x6f 0x13 0x72 0x13 0x70>;
				clock-names = "mdp_core", "iface", "bus", "byte", "pixel", "core";
				phys = <0x4b>;
				#address-cells = <0x01>;
				#size-cells = <0x00>;
				vdda-supply = <0x4f>;
				vddio-supply = <0x50>;
				pinctrl-0 = <0x51>;
				pinctrl-1 = <0x52>;

				ports {
					#address-cells = <0x01>;
					#size-cells = <0x00>;

					port@0 {
						reg = <0x00>;

						endpoint {
							remote-endpoint = <0x53>;
							phandle = <0x4e>;
						};
					};

					port@1 {
						reg = <0x01>;

						endpoint {
							data-lanes = <0x00 0x01 0x02 0x03>;
							remote-endpoint = <0x54>;
							phandle = <0x57>;
						};
					};
				};

				panel@0 {
					compatible = "oppo,a37-boe-ili9881c";
					reg = <0x00>;
					backlight = <0x55>;
					power-supply = <0x56>;
					reset-gpios = <0x49 0x19 0x01>;

					port {

						endpoint {
							remote-endpoint = <0x57>;
							phandle = <0x54>;
						};
					};
				};
			};

			phy@1a98300 {
				compatible = "qcom,dsi-phy-28nm-lp";
				reg = <0x1a98300 0xd4 0x1a98500 0x280 0x1a98780 0x30>;
				reg-names = "dsi_pll", "dsi_phy", "dsi_phy_regulator";
				#clock-cells = <0x01>;
				#phy-cells = <0x00>;
				clocks = <0x13 0x6d 0x1b>;
				clock-names = "iface", "ref";
				vddio-supply = <0x50>;
				qcom,dsi-phy-regulator-ldo-mode;
				phandle = <0x4b>;
			};
		};

		camss@1b0ac00 {
			compatible = "qcom,msm8916-camss";
			reg = <0x1b0ac00 0x200 0x1b00030 0x04 0x1b0b000 0x200 0x1b00038 0x04 0x1b08000 0x100 0x1b08400 0x100 0x1b0a000 0x500 0x1b00020 0x10 0x1b10000 0x1000>;
			reg-names = "csiphy0", "csiphy0_clk_mux", "csiphy1", "csiphy1_clk_mux", "csid0", "csid1", "ispif", "csi_clk_mux", "vfe0";
			interrupts = <0x00 0x4e 0x01 0x00 0x4f 0x01 0x00 0x33 0x01 0x00 0x34 0x01 0x00 0x37 0x01 0x00 0x39 0x01>;
			interrupt-names = "csiphy0", "csiphy1", "csid0", "csid1", "ispif", "vfe0";
			power-domains = <0x13 0x04>;
			clocks = <0x13 0x60 0x13 0x56 0x13 0x5d 0x13 0x5e 0x13 0x49 0x13 0x4a 0x13 0x4b 0x13 0x4c 0x13 0x4d 0x13 0x4e 0x13 0x4f 0x13 0x50 0x13 0x51 0x13 0x52 0x13 0x5f 0x13 0x63 0x13 0x53 0x13 0x64 0x13 0x65>;
			clock-names = "top_ahb", "ispif_ahb", "csiphy0_timer", "csiphy1_timer", "csi0_ahb", "csi0", "csi0_phy", "csi0_pix", "csi0_rdi", "csi1_ahb", "csi1", "csi1_phy", "csi1_pix", "csi1_rdi", "ahb", "vfe0", "csi_vfe0", "vfe_ahb", "vfe_axi";
			iommus = <0x4d 0x03>;
			status = "disabled";
			vdda-supply = <0x4f>;

			ports {
				#address-cells = <0x01>;
				#size-cells = <0x00>;

				port@0 {
					reg = <0x00>;
				};

				port@1 {
					reg = <0x01>;
				};
			};
		};

		cci@1b0c000 {
			compatible = "qcom,msm8916-cci", "qcom,msm8226-cci";
			#address-cells = <0x01>;
			#size-cells = <0x00>;
			reg = <0x1b0c000 0x1000>;
			interrupts = <0x00 0x32 0x01>;
			clocks = <0x13 0x60 0x13 0x47 0x13 0x48 0x13 0x5f>;
			clock-names = "camss_top_ahb", "cci_ahb", "cci", "camss_ahb";
			assigned-clocks = <0x13 0x47 0x13 0x48>;
			assigned-clock-rates = <0x4c4b400 0x124f800>;
			pinctrl-names = "default";
			pinctrl-0 = <0x58>;
			status = "disabled";

			i2c-bus@0 {
				reg = <0x00>;
				clock-frequency = <0x61a80>;
				#address-cells = <0x01>;
				#size-cells = <0x00>;
			};
		};

		gpu@1c00000 {
			compatible = "qcom,adreno-306.0", "qcom,adreno";
			reg = <0x1c00000 0x20000>;
			reg-names = "kgsl_3d0_reg_memory";
			interrupts = <0x00 0x21 0x04>;
			interrupt-names = "kgsl_3d0_irq";
			clock-names = "core", "iface", "mem", "mem_iface", "alt_mem_iface", "gfx3d";
			clocks = <0x13 0x76 0x13 0x75 0x13 0x69 0x13 0x8e 0x13 0x8f 0x13 0x0e>;
			power-domains = <0x13 0x05>;
			operating-points-v2 = <0x59>;
			iommus = <0x5a 0x01 0x5a 0x02>;
			#cooling-cells = <0x02>;
			status = "okay";
			phandle = <0xad>;

			opp-table {
				compatible = "operating-points-v2";
				phandle = <0x59>;

				opp-400000000 {
					opp-hz = <0x00 0x17d78400>;
				};

				opp-19200000 {
					opp-hz = <0x00 0x124f800>;
				};
			};
		};

		video-codec@1d00000 {
			compatible = "qcom,msm8916-venus";
			reg = <0x1d00000 0xff000>;
			interrupts = <0x00 0x2c 0x04>;
			power-domains = <0x13 0x01>;
			clocks = <0x13 0x89 0x13 0x87 0x13 0x88>;
			clock-names = "core", "iface", "bus";
			iommus = <0x4d 0x05>;
			memory-region = <0x5b>;
			status = "okay";

			video-decoder {
				compatible = "venus-decoder";
			};

			video-encoder {
				compatible = "venus-encoder";
			};
		};

		iommu@1ef0000 {
			#address-cells = <0x01>;
			#size-cells = <0x01>;
			#iommu-cells = <0x01>;
			compatible = "qcom,msm8916-iommu", "qcom,msm-iommu-v1";
			ranges = <0x00 0x1e20000 0x20000>;
			reg = <0x1ef0000 0x3000>;
			clocks = <0x13 0x81 0x13 0x8b>;
			clock-names = "iface", "bus";
			qcom,iommu-secure-id = <0x11>;
			phandle = <0x4d>;

			iommu-ctx@3000 {
				compatible = "qcom,msm-iommu-v1-sec";
				reg = <0x3000 0x1000>;
				interrupts = <0x00 0x46 0x04>;
			};

			iommu-ctx@4000 {
				compatible = "qcom,msm-iommu-v1-ns";
				reg = <0x4000 0x1000>;
				interrupts = <0x00 0x46 0x04>;
			};

			iommu-ctx@5000 {
				compatible = "qcom,msm-iommu-v1-sec";
				reg = <0x5000 0x1000>;
				interrupts = <0x00 0x46 0x04>;
			};
		};

		iommu@1f08000 {
			#address-cells = <0x01>;
			#size-cells = <0x01>;
			#iommu-cells = <0x01>;
			compatible = "qcom,msm8916-iommu", "qcom,msm-iommu-v1";
			ranges = <0x00 0x1f08000 0x10000>;
			clocks = <0x13 0x81 0x13 0x8c>;
			clock-names = "iface", "bus";
			qcom,iommu-secure-id = <0x12>;
			phandle = <0x5a>;

			iommu-ctx@1000 {
				compatible = "qcom,msm-iommu-v1-ns";
				reg = <0x1000 0x1000>;
				interrupts = <0x00 0xf1 0x04>;
			};

			iommu-ctx@2000 {
				compatible = "qcom,msm-iommu-v1-ns";
				reg = <0x2000 0x1000>;
				interrupts = <0x00 0xf2 0x04>;
			};
		};

		spmi@200f000 {
			compatible = "qcom,spmi-pmic-arb";
			reg = <0x200f000 0x1000 0x2400000 0x400000 0x2c00000 0x400000 0x3800000 0x200000 0x200a000 0x2100>;
			reg-names = "core", "chnls", "obsrvr", "intr", "cnfg";
			interrupt-names = "periph_irq";
			interrupts = <0x00 0xbe 0x04>;
			qcom,ee = <0x00>;
			qcom,channel = <0x00>;
			#address-cells = <0x02>;
			#size-cells = <0x00>;
			interrupt-controller;
			#interrupt-cells = <0x04>;
			phandle = <0x61>;

			pmic@0 {
				compatible = "qcom,pm8916", "qcom,spmi-pmic";
				reg = <0x00 0x00>;
				#address-cells = <0x01>;
				#size-cells = <0x00>;

				pon@800 {
					compatible = "qcom,pm8916-pon";
					reg = <0x800>;
					mode-bootloader = <0x02>;
					mode-recovery = <0x01>;

					pwrkey {
						compatible = "qcom,pm8941-pwrkey";
						interrupts = <0x00 0x08 0x00 0x03>;
						debounce = <0x3d09>;
						bias-pull-up;
						linux,code = <0x74>;
					};

					resin {
						compatible = "qcom,pm8941-resin";
						interrupts = <0x00 0x08 0x01 0x03>;
						debounce = <0x3d09>;
						bias-pull-up;
						status = "disabled";
					};

					watchdog {
						compatible = "qcom,pm8916-wdt";
						interrupts = <0x00 0x08 0x06 0x01>;
						timeout-sec = <0x3c>;
					};
				};

				charger@1000 {
					compatible = "qcom,pm8916-lbc";
					reg = <0x1000 0x1200 0x1300 0x1600>;
					reg-names = "chgr", "bat_if", "usb", "misc";
					interrupts = <0x00 0x10 0x00 0x03 0x00 0x10 0x05 0x03 0x00 0x10 0x06 0x03 0x00 0x10 0x07 0x03 0x00 0x12 0x00 0x03 0x00 0x12 0x01 0x03 0x00 0x13 0x00 0x03 0x00 0x13 0x01 0x03 0x00 0x13 0x02 0x03 0x00 0x13 0x04 0x03>;
					interrupt-names = "vbat_det", "fast_chg", "chg_fail", "chg_done", "bat_pres", "temp_ok", "coarse_det", "usb_vbus", "chg_gone", "overtemp";
					status = "disabled";
				};

				usb-detect@1300 {
					compatible = "qcom,pm8941-misc";
					reg = <0x1300>;
					interrupts = <0x00 0x13 0x01 0x03>;
					interrupt-names = "usb_vbus";
					status = "okay";
				};

				temp-alarm@2400 {
					compatible = "qcom,spmi-temp-alarm";
					reg = <0x2400>;
					interrupts = <0x00 0x24 0x00 0x01>;
					io-channels = <0x5c 0x08>;
					io-channel-names = "thermal";
					#thermal-sensor-cells = <0x00>;
					phandle = <0xae>;
				};

				adc@3100 {
					compatible = "qcom,spmi-vadc";
					reg = <0x3100>;
					interrupts = <0x00 0x31 0x00 0x01>;
					#address-cells = <0x01>;
					#size-cells = <0x00>;
					#io-channel-cells = <0x01>;
					phandle = <0x5c>;

					channel@0 {
						reg = <0x00>;
						qcom,pre-scaling = <0x01 0x0a>;
					};

					channel@7 {
						reg = <0x07>;
						qcom,pre-scaling = <0x01 0x03>;
					};

					channel@8 {
						reg = <0x08>;
					};

					channel@9 {
						reg = <0x09>;
					};

					channel@a {
						reg = <0x0a>;
					};

					channel@e {
						reg = <0x0e>;
					};

					channel@f {
						reg = <0x0f>;
					};
				};

				battery@4000 {
					compatible = "qcom,pm8916-bms-vm";
					reg = <0x4000>;
					interrupts = <0x00 0x40 0x00 0x01 0x00 0x40 0x01 0x01 0x00 0x40 0x02 0x01 0x00 0x40 0x03 0x01 0x00 0x40 0x04 0x01 0x00 0x40 0x05 0x01>;
					interrupt-names = "cv_leave", "cv_enter", "ocv_good", "ocv_thr", "fifo", "state_chg";
					status = "okay";
					monitored-battery = <0x5d>;
					power-supplies = <0x5e>;
				};

				rtc@6000 {
					compatible = "qcom,pm8941-rtc";
					reg = <0x6000 0x6100>;
					reg-names = "rtc", "alarm";
					interrupts = <0x00 0x61 0x01 0x01>;
				};

				mpps@a000 {
					compatible = "qcom,pm8916-mpp", "qcom,spmi-mpp";
					reg = <0xa000>;
					gpio-controller;
					#gpio-cells = <0x02>;
					gpio-ranges = <0x5f 0x00 0x00 0x04>;
					interrupt-controller;
					#interrupt-cells = <0x02>;
					phandle = <0x5f>;
				};

				gpio@c000 {
					compatible = "qcom,pm8916-gpio", "qcom,spmi-gpio";
					reg = <0xc000>;
					gpio-controller;
					gpio-ranges = <0x60 0x00 0x00 0x04>;
					#gpio-cells = <0x02>;
					interrupt-controller;
					#interrupt-cells = <0x02>;
					phandle = <0x60>;
				};
			};

			pmic@1 {
				compatible = "qcom,pm8916", "qcom,spmi-pmic";
				reg = <0x01 0x00>;
				#address-cells = <0x01>;
				#size-cells = <0x00>;

				pwm {
					compatible = "qcom,pm8916-pwm";
					#pwm-cells = <0x02>;
					status = "disabled";
				};

				vibrator@c000 {
					compatible = "qcom,pm8916-vib";
					reg = <0xc000>;
					status = "okay";
				};

				audio-codec@f000 {
					compatible = "qcom,pm8916-wcd-analog-codec";
					reg = <0xf000>;
					interrupt-parent = <0x61>;
					interrupts = <0x01 0xf0 0x00 0x00 0x01 0xf0 0x01 0x00 0x01 0xf0 0x02 0x00 0x01 0xf0 0x03 0x00 0x01 0xf0 0x04 0x00 0x01 0xf0 0x05 0x00 0x01 0xf0 0x06 0x00 0x01 0xf0 0x07 0x00 0x01 0xf1 0x00 0x00 0x01 0xf1 0x01 0x00 0x01 0xf1 0x02 0x00 0x01 0xf1 0x03 0x00 0x01 0xf1 0x04 0x00 0x01 0xf1 0x05 0x00>;
					interrupt-names = "cdc_spk_cnp_int", "cdc_spk_clip_int", "cdc_spk_ocp_int", "mbhc_ins_rem_det1", "mbhc_but_rel_det", "mbhc_but_press_det", "mbhc_ins_rem_det", "mbhc_switch_int", "cdc_ear_ocp_int", "cdc_hphr_ocp_int", "cdc_hphl_ocp_det", "cdc_ear_cnp_int", "cdc_hphr_cnp_int", "cdc_hphl_cnp_int";
					#sound-dai-cells = <0x01>;
					status = "okay";
					vdd-cdc-io-supply = <0x62>;
					vdd-cdc-tx-rx-cx-supply = <0x62>;
					vdd-micbias-supply = <0x63>;
					qcom,micbias-lvl = <0xaf0>;
					qcom,mbhc-vthreshold-low = <0x4b 0x96 0xed 0x1c2 0x1f4>;
					qcom,mbhc-vthreshold-high = <0x4b 0x96 0xed 0x1c2 0x1f4>;
					qcom,hphl-jack-type-normally-open;
					phandle = <0x75>;
				};
			};
		};

		dma-controller@4044000 {
			compatible = "qcom,bam-v1.7.0";
			reg = <0x4044000 0x19000>;
			interrupts = <0x00 0x1d 0x04>;
			#dma-cells = <0x01>;
			qcom,ee = <0x00>;
			num-channels = <0x06>;
			qcom,num-ees = <0x01>;
			qcom,powered-remotely;
			status = "okay";
			phandle = <0x6d>;
		};

		remoteproc@4080000 {
			compatible = "qcom,msm8916-mss-pil";
			reg = <0x4080000 0x100 0x4020000 0x40>;
			reg-names = "qdsp6", "rmb";
			interrupts-extended = <0x01 0x00 0x18 0x01 0x64 0x00 0x01 0x64 0x01 0x01 0x64 0x02 0x01 0x64 0x03 0x01>;
			interrupt-names = "wdog", "fatal", "ready", "handover", "stop-ack";
			power-domains = <0x65 0x00 0x65 0x03>;
			power-domain-names = "cx", "mx";
			clocks = <0x13 0x74 0x13 0xa0 0x13 0x46 0x1b>;
			clock-names = "iface", "bus", "mem", "xo";
			qcom,smem-states = <0x66 0x00>;
			qcom,smem-state-names = "stop";
			resets = <0x67 0x00>;
			reset-names = "mss_restart";
			qcom,halt-regs = <0x14 0x18000 0x19000 0x1a000>;
			status = "okay";
			pll-supply = <0x68>;

			mba {
				memory-region = <0x69>;
			};

			mpss {
				memory-region = <0x6a>;
			};

			bam-dmux {
				compatible = "qcom,bam-dmux";
				interrupt-parent = <0x6b>;
				interrupts = <0x01 0x03 0x0b 0x03>;
				interrupt-names = "pc", "pc-ack";
				qcom,smem-states = <0x6c 0x01 0x6c 0x0b>;
				qcom,smem-state-names = "pc", "pc-ack";
				dmas = <0x6d 0x04 0x6d 0x05>;
				dma-names = "tx", "rx";
				status = "okay";
			};

			smd-edge {
				interrupts = <0x00 0x19 0x01>;
				qcom,smd-edge = <0x00>;
				mboxes = <0x05 0x0c>;
				qcom,remote-pid = <0x01>;
				label = "hexagon";

				apr {
					compatible = "qcom,apr-v2";
					qcom,smd-channels = "apr_audio_svc";
					qcom,domain = <0x04>;
					#address-cells = <0x01>;
					#size-cells = <0x00>;
					status = "okay";

					service@3 {
						compatible = "qcom,q6core";
						reg = <0x03>;
					};

					service@4 {
						compatible = "qcom,q6afe";
						reg = <0x04>;

						dais {
							compatible = "qcom,q6afe-dais";
							#address-cells = <0x01>;
							#size-cells = <0x00>;
							#sound-dai-cells = <0x01>;
							phandle = <0x72>;

							dai@16 {
								reg = <0x10>;
								qcom,sd-lines = <0x00 0x01>;
							};

							dai@20 {
								reg = <0x15>;
								qcom,sd-lines = <0x00 0x01>;
							};
						};
					};

					service@7 {
						compatible = "qcom,q6asm";
						reg = <0x07>;

						dais {
							compatible = "qcom,q6asm-dais";
							#address-cells = <0x01>;
							#size-cells = <0x00>;
							#sound-dai-cells = <0x01>;
							phandle = <0x70>;

							dai@0 {
								reg = <0x00>;
								direction = <0x02>;
							};

							dai@1 {
								reg = <0x01>;
								direction = <0x01>;
							};

							dai@2 {
								reg = <0x02>;
								direction = <0x02>;
							};

							dai@3 {
								reg = <0x03>;
								direction = <0x02>;
								is-compress-dai;
							};
						};
					};

					service@8 {
						compatible = "qcom,q6adm";
						reg = <0x08>;

						routing {
							compatible = "qcom,q6adm-routing";
							#sound-dai-cells = <0x00>;
							phandle = <0x73>;
						};
					};

					apr-service@9 {
						compatible = "qcom,q6mvm";
						reg = <0x09>;

						dais {
							compatible = "qcom,q6voice-dais";
							#sound-dai-cells = <0x00>;
							phandle = <0x71>;
						};
					};

					apr-service@a {
						compatible = "qcom,q6cvs";
						reg = <0x0a>;
					};

					apr-service@b {
						compatible = "qcom,q6cvp";
						reg = <0x0b>;
					};
				};

				fastrpc {
					compatible = "qcom,fastrpc";
					qcom,smd-channels = "fastrpcsmd-apps-dsp";
					label = "adsp";
					qcom,non-secure-domain;
					#address-cells = <0x01>;
					#size-cells = <0x00>;

					cb@1 {
						compatible = "qcom,fastrpc-compute-cb";
						reg = <0x01>;
					};
				};
			};
		};

		sound@7702000 {
			status = "okay";
			compatible = "qcom,msm8916-qdsp6-sndcard";
			reg = <0x7702000 0x04 0x7702004 0x04>;
			reg-names = "mic-iomux", "spkr-iomux";
			model = "oppo-a51f";
			pinctrl-0 = <0x6e>;
			pinctrl-1 = <0x6f>;
			pinctrl-names = "default", "sleep";
			widgets = "Speaker", "Speaker", "Headphone", "Headphones";
			pin-switches = "Speaker", "Headphones";
			audio-routing = "Speaker", "Speaker Amp OUTL", "Speaker", "Speaker Amp OUTR", "Speaker Amp INL", "HPH_L", "Speaker Amp INR", "HPH_R", "AMIC1", "MIC BIAS Internal1", "AMIC2", "MIC BIAS Internal2", "AMIC3", "MIC BIAS Internal3";
			aux-devs = <0xb3>;

			frontend0-dai-link {
				link-name = "MultiMedia1";

				cpu {
					sound-dai = <0x70 0x00>;
				};
			};

			frontend1-dai-link {
				link-name = "MultiMedia2";

				cpu {
					sound-dai = <0x70 0x01>;
				};
			};

			frontend2-dai-link {
				link-name = "MultiMedia3";

				cpu {
					sound-dai = <0x70 0x02>;
				};
			};

			frontend3-dai-link {
				link-name = "MultiMedia4";

				cpu {
					sound-dai = <0x70 0x03>;
				};
			};

			frontend4-dai-link {
				link-name = "CS-Voice";

				cpu {
					sound-dai = <0x71 0x00>;
				};
			};

			backend0-dai-link {
				link-name = "Primary MI2S";

				cpu {
					sound-dai = <0x72 0x10>;
				};

				platform {
					sound-dai = <0x73>;
				};

				codec {
					sound-dai = <0x74 0x00 0x75 0x00>;
				};
			};

			backend1-dai-link {
				link-name = "Tertiary MI2S";

				cpu {
					sound-dai = <0x72 0x15>;
				};

				platform {
					sound-dai = <0x73>;
				};

				codec {
					sound-dai = <0x74 0x01 0x75 0x01>;
				};
			};
		};

		audio-controller@7708000 {
			status = "reserved";
			compatible = "qcom,apq8016-lpass-cpu";
			clocks = <0x13 0x9a 0x13 0x9c 0x13 0x9c 0x13 0x9d 0x13 0x9e 0x13 0x96 0x13 0x97>;
			clock-names = "ahbix-clk", "mi2s-bit-clk0", "mi2s-bit-clk1", "mi2s-bit-clk2", "mi2s-bit-clk3", "pcnoc-mport-clk", "pcnoc-sway-clk";
			#sound-dai-cells = <0x01>;
			interrupts = <0x00 0xa0 0x04>;
			interrupt-names = "lpass-irq-lpaif";
			reg = <0x7708000 0x10000>;
			reg-names = "lpass-lpaif";
			#address-cells = <0x01>;
			#size-cells = <0x00>;
		};

		audio-codec@771c000 {
			compatible = "qcom,msm8916-wcd-digital-codec";
			reg = <0x771c000 0x400>;
			clocks = <0x13 0x9a 0x13 0x9f>;
			clock-names = "ahbix-clk", "mclk";
			#sound-dai-cells = <0x01>;
			status = "okay";
			phandle = <0x74>;
		};

		mmc@7824900 {
			compatible = "qcom,msm8916-sdhci", "qcom,sdhci-msm-v4";
			reg = <0x7824900 0x11c 0x7824000 0x800>;
			reg-names = "hc", "core";
			interrupts = <0x00 0x7b 0x04 0x00 0x8a 0x04>;
			interrupt-names = "hc_irq", "pwr_irq";
			clocks = <0x13 0x7a 0x13 0x7b 0x1b>;
			clock-names = "iface", "core", "xo";
			pinctrl-0 = <0x76>;
			pinctrl-1 = <0x77>;
			pinctrl-names = "default", "sleep";
			mmc-ddr-1_8v;
			bus-width = <0x08>;
			non-removable;
			status = "okay";
			vmmc-supply = <0x78>;
			vqmmc-supply = <0x62>;
		};

		mmc@7864900 {
			compatible = "qcom,msm8916-sdhci", "qcom,sdhci-msm-v4";
			reg = <0x7864900 0x11c 0x7864000 0x800>;
			reg-names = "hc", "core";
			interrupts = <0x00 0x7d 0x04 0x00 0xdd 0x04>;
			interrupt-names = "hc_irq", "pwr_irq";
			clocks = <0x13 0x7c 0x13 0x7d 0x1b>;
			clock-names = "iface", "core", "xo";
			pinctrl-0 = <0x79 0x7a>;
			pinctrl-1 = <0x7b 0x7a>;
			pinctrl-names = "default", "sleep";
			bus-width = <0x04>;
			status = "okay";
			vmmc-supply = <0x7c>;
			vqmmc-supply = <0x7d>;
			cd-gpios = <0x00>;
			broken-cd;
		};

		dma-controller@7884000 {
			compatible = "qcom,bam-v1.7.0";
			reg = <0x7884000 0x23000>;
			interrupts = <0x00 0xee 0x04>;
			clocks = <0x13 0x36>;
			clock-names = "bam_clk";
			#dma-cells = <0x01>;
			qcom,ee = <0x00>;
			qcom,controlled-remotely;
			phandle = <0x7e>;
		};

		serial@78af000 {
			compatible = "qcom,msm-uartdm-v1.4", "qcom,msm-uartdm";
			reg = <0x78af000 0x200>;
			interrupts = <0x00 0x6b 0x04>;
			clocks = <0x13 0x44 0x13 0x36>;
			clock-names = "core", "iface";
			dmas = <0x7e 0x00 0x7e 0x01>;
			dma-names = "tx", "rx";
			pinctrl-names = "default", "sleep";
			pinctrl-0 = <0x7f>;
			pinctrl-1 = <0x80>;
			status = "disabled";
		};

		serial@78b0000 {
			compatible = "qcom,msm-uartdm-v1.4", "qcom,msm-uartdm";
			reg = <0x78b0000 0x200>;
			interrupts = <0x00 0x6c 0x04>;
			clocks = <0x13 0x45 0x13 0x36>;
			clock-names = "core", "iface";
			dmas = <0x7e 0x02 0x7e 0x03>;
			dma-names = "tx", "rx";
			pinctrl-names = "default", "sleep";
			pinctrl-0 = <0x81>;
			pinctrl-1 = <0x82>;
			status = "okay";
		};

		i2c@78b5000 {
			compatible = "qcom,i2c-qup-v2.2.1";
			reg = <0x78b5000 0x500>;
			interrupts = <0x00 0x5f 0x04>;
			clocks = <0x13 0x38 0x13 0x36>;
			clock-names = "core", "iface";
			dmas = <0x7e 0x04 0x7e 0x05>;
			dma-names = "tx", "rx";
			pinctrl-names = "default", "sleep";
			pinctrl-0 = <0x83>;
			pinctrl-1 = <0x84>;
			#address-cells = <0x01>;
			#size-cells = <0x00>;
			status = "disabled";
		};

		spi@78b5000 {
			compatible = "qcom,spi-qup-v2.2.1";
			reg = <0x78b5000 0x500>;
			interrupts = <0x00 0x5f 0x04>;
			clocks = <0x13 0x39 0x13 0x36>;
			clock-names = "core", "iface";
			dmas = <0x7e 0x04 0x7e 0x05>;
			dma-names = "tx", "rx";
			pinctrl-names = "default", "sleep";
			pinctrl-0 = <0x85>;
			pinctrl-1 = <0x86>;
			#address-cells = <0x01>;
			#size-cells = <0x00>;
			status = "disabled";
		};

		i2c@78b6000 {
			compatible = "qcom,i2c-qup-v2.2.1";
			reg = <0x78b6000 0x500>;
			interrupts = <0x00 0x60 0x04>;
			clocks = <0x13 0x3a 0x13 0x36>;
			clock-names = "core", "iface";
			dmas = <0x7e 0x06 0x7e 0x07>;
			dma-names = "tx", "rx";
			pinctrl-names = "default", "sleep";
			pinctrl-0 = <0x87>;
			pinctrl-1 = <0x88>;
			#address-cells = <0x01>;
			#size-cells = <0x00>;
			status = "okay";

			accelerometer@19 {
				compatible = "st,lis3dh-accel";
				reg = <0x19>;
				vdd-supply = <0x89>;
				vddio-supply = <0x50>;
				mount-matrix = "0", "-1", "0", "1", "0", "0", "0", "0", "1";
			};
		};

		spi@78b6000 {
			compatible = "qcom,spi-qup-v2.2.1";
			reg = <0x78b6000 0x500>;
			interrupts = <0x00 0x60 0x04>;
			clocks = <0x13 0x3b 0x13 0x36>;
			clock-names = "core", "iface";
			dmas = <0x7e 0x06 0x7e 0x07>;
			dma-names = "tx", "rx";
			pinctrl-names = "default", "sleep";
			pinctrl-0 = <0x8a>;
			pinctrl-1 = <0x8b>;
			#address-cells = <0x01>;
			#size-cells = <0x00>;
			status = "disabled";
		};

		i2c@78b7000 {
			compatible = "qcom,i2c-qup-v2.2.1";
			reg = <0x78b7000 0x500>;
			interrupts = <0x00 0x61 0x04>;
			clocks = <0x13 0x3c 0x13 0x36>;
			clock-names = "core", "iface";
			dmas = <0x7e 0x08 0x7e 0x09>;
			dma-names = "tx", "rx";
			pinctrl-names = "default", "sleep";
			pinctrl-0 = <0x8c>;
			pinctrl-1 = <0x8d>;
			#address-cells = <0x01>;
			#size-cells = <0x00>;
			status = "disabled";
		};

		spi@78b7000 {
			compatible = "qcom,spi-qup-v2.2.1";
			reg = <0x78b7000 0x500>;
			interrupts = <0x00 0x61 0x04>;
			clocks = <0x13 0x3d 0x13 0x36>;
			clock-names = "core", "iface";
			dmas = <0x7e 0x08 0x7e 0x09>;
			dma-names = "tx", "rx";
			pinctrl-names = "default", "sleep";
			pinctrl-0 = <0x8e>;
			pinctrl-1 = <0x8f>;
			#address-cells = <0x01>;
			#size-cells = <0x00>;
			status = "disabled";
		};

		i2c@78b8000 {
			compatible = "qcom,i2c-qup-v2.2.1";
			reg = <0x78b8000 0x500>;
			interrupts = <0x00 0x62 0x04>;
			clocks = <0x13 0x3e 0x13 0x36>;
			clock-names = "core", "iface";
			dmas = <0x7e 0x0a 0x7e 0x0b>;
			dma-names = "tx", "rx";
			pinctrl-names = "default", "sleep";
			pinctrl-0 = <0x90>;
			pinctrl-1 = <0x91>;
			#address-cells = <0x01>;
			#size-cells = <0x00>;
			status = "okay";

			charger@6b {
				compatible = "ti,bq24196";
				reg = <0x6b>;
				interrupt-parent = <0x49>;
				interrupts = <0x3e 0x02>;
				pinctrl-names = "default";
				pinctrl-0 = <0x92>;
				monitored-battery = <0x5d>;
				ti,system-minimum-microvolt = <0x30d400>;
				phandle = <0x5e>;

				usb-otg-vbus {
					regulator-name = "usb_otg_vbus";
					regulator-min-microvolt = <0x4ac4a0>;
					regulator-max-microvolt = <0x4f5880>;
				};
			};
		};

		spi@78b8000 {
			compatible = "qcom,spi-qup-v2.2.1";
			reg = <0x78b8000 0x500>;
			interrupts = <0x00 0x62 0x04>;
			clocks = <0x13 0x3f 0x13 0x36>;
			clock-names = "core", "iface";
			dmas = <0x7e 0x0a 0x7e 0x0b>;
			dma-names = "tx", "rx";
			pinctrl-names = "default", "sleep";
			pinctrl-0 = <0x93>;
			pinctrl-1 = <0x94>;
			#address-cells = <0x01>;
			#size-cells = <0x00>;
			status = "disabled";
		};

		i2c@78b9000 {
			compatible = "qcom,i2c-qup-v2.2.1";
			reg = <0x78b9000 0x500>;
			interrupts = <0x00 0x63 0x04>;
			clocks = <0x13 0x40 0x13 0x36>;
			clock-names = "core", "iface";
			dmas = <0x7e 0x0c 0x7e 0x0d>;
			dma-names = "tx", "rx";
			pinctrl-names = "default", "sleep";
			pinctrl-0 = <0x95>;
			pinctrl-1 = <0x96>;
			#address-cells = <0x01>;
			#size-cells = <0x00>;
			status = "okay";

			touchscreen@20 {
				compatible = "syna,rmi4-i2c";
				reg = <0x20>;
				#address-cells = <0x01>;
				#size-cells = <0x00>;
				interrupt-parent = <0x49>;
				interrupts = <0x0d 0x02>;
				vdd-supply = <0x89>;
				vio-supply = <0x50>;
				pinctrl-names = "default";
				pinctrl-0 = <0x97>;
				syna,startup-delay-ms = <0x0a>;

				rmi4-f01@1 {
					reg = <0x01>;
					syna,nosleep-mode = <0x01>;
				};

				rmi4-f11@11 {
					reg = <0x11>;
					syna,sensor-type = <0x01>;
					touchscreen-x-mm = <0x3e>;
					touchscreen-y-mm = <0x78>;
				};
			};

			backlight@38 {
				compatible = "ti,lm3630a";
				reg = <0x38>;
				#address-cells = <0x01>;
				#size-cells = <0x00>;
				enable-gpios = <0x49 0x45 0x00>;
				pinctrl-names = "default";
				pinctrl-0 = <0x98>;
				phandle = <0x55>;

				led@0 {
					reg = <0x00>;
					led-sources = <0x00 0x01>;
					label = "lcd-backlight";
					default-brightness = <0xc8>;
					max-brightness = <0xff>;
				};
			};
		};

		spi@78b9000 {
			compatible = "qcom,spi-qup-v2.2.1";
			reg = <0x78b9000 0x500>;
			interrupts = <0x00 0x63 0x04>;
			clocks = <0x13 0x41 0x13 0x36>;
			clock-names = "core", "iface";
			dmas = <0x7e 0x0c 0x7e 0x0d>;
			dma-names = "tx", "rx";
			pinctrl-names = "default", "sleep";
			pinctrl-0 = <0x99>;
			pinctrl-1 = <0x9a>;
			#address-cells = <0x01>;
			#size-cells = <0x00>;
			status = "disabled";
		};

		i2c@78ba000 {
			compatible = "qcom,i2c-qup-v2.2.1";
			reg = <0x78ba000 0x500>;
			interrupts = <0x00 0x64 0x04>;
			clocks = <0x13 0x42 0x13 0x36>;
			clock-names = "core", "iface";
			dmas = <0x7e 0x0e 0x7e 0x0f>;
			dma-names = "tx", "rx";
			pinctrl-names = "default", "sleep";
			pinctrl-0 = <0x9b>;
			pinctrl-1 = <0x9c>;
			#address-cells = <0x01>;
			#size-cells = <0x00>;
			status = "disabled";
		};

		spi@78ba000 {
			compatible = "qcom,spi-qup-v2.2.1";
			reg = <0x78ba000 0x500>;
			interrupts = <0x00 0x64 0x04>;
			clocks = <0x13 0x43 0x13 0x36>;
			clock-names = "core", "iface";
			dmas = <0x7e 0x0e 0x7e 0x0f>;
			dma-names = "tx", "rx";
			pinctrl-names = "default", "sleep";
			pinctrl-0 = <0x9d>;
			pinctrl-1 = <0x9e>;
			#address-cells = <0x01>;
			#size-cells = <0x00>;
			status = "disabled";
		};

		usb@78d9000 {
			compatible = "qcom,ci-hdrc";
			reg = <0x78d9000 0x200 0x78d9200 0x200>;
			interrupts = <0x00 0x86 0x04 0x00 0x8c 0x04>;
			clocks = <0x13 0x85 0x13 0x86>;
			clock-names = "iface", "core";
			assigned-clocks = <0x13 0x86>;
			assigned-clock-rates = <0x4c4b400>;
			resets = <0x13 0x22>;
			reset-names = "core";
			phy_type = "ulpi";
			dr_mode = "peripheral";
			hnp-disable;
			srp-disable;
			adp-disable;
			ahb-burst-config = <0x00>;
			phy-names = "usb-phy";
			phys = <0x9f>;
			status = "okay";
			#reset-cells = <0x01>;
			extcon = <0xa0>;
			phandle = <0xa1>;

			ulpi {

				phy {
					compatible = "qcom,usb-hs-phy-msm8916", "qcom,usb-hs-phy";
					#phy-cells = <0x00>;
					clocks = <0x1b 0x13 0x84>;
					clock-names = "ref", "sleep";
					resets = <0x13 0x23 0xa1 0x00>;
					reset-names = "phy", "por";
					qcom,init-seq = [00 44 00 00 00 01 00 00 00 6b 00 00 00 02 00 00 00 24 00 00 00 03 00 00 00 13];
					v1p8-supply = <0x68>;
					v3p3-supply = <0x63>;
					extcon = <0xa0>;
					phandle = <0x9f>;
				};
			};
		};

		remoteproc@a204000 {
			compatible = "qcom,pronto-v2-pil", "qcom,pronto";
			reg = <0xa204000 0x2000 0xa202000 0x1000 0xa21b000 0x3000>;
			reg-names = "ccu", "dxe", "pmu";
			memory-region = <0xa2>;
			interrupts-extended = <0x01 0x00 0x95 0x01 0xa3 0x00 0x01 0xa3 0x01 0x01 0xa3 0x02 0x01 0xa3 0x03 0x01>;
			interrupt-names = "wdog", "fatal", "ready", "handover", "stop-ack";
			power-domains = <0x65 0x00 0x65 0x03>;
			power-domain-names = "cx", "mx";
			qcom,smem-states = <0xa4 0x00>;
			qcom,smem-state-names = "stop";
			pinctrl-names = "default";
			pinctrl-0 = <0xa5>;
			status = "okay";
			vddpx-supply = <0x68>;
			phandle = <0xa7>;

			iris {
				clocks = <0x2c 0x10>;
				clock-names = "xo";
				vddxo-supply = <0x68>;
				vddrfa-supply = <0x1d>;
				vddpa-supply = <0xa6>;
				vdddig-supply = <0x62>;
				compatible = "qcom,wcn3620";
			};

			smd-edge {
				interrupts = <0x00 0x8e 0x01>;
				mboxes = <0x05 0x11>;
				qcom,smd-edge = <0x06>;
				qcom,remote-pid = <0x04>;
				label = "pronto";

				wcnss {
					compatible = "qcom,wcnss";
					qcom,smd-channels = "WCNSS_CTRL";
					qcom,mmio = <0xa7>;

					bluetooth {
						compatible = "qcom,wcnss-bt";
					};

					wifi {
						compatible = "qcom,wcnss-wlan";
						interrupts = <0x00 0x91 0x04 0x00 0x92 0x04>;
						interrupt-names = "tx", "rx";
						qcom,smem-states = <0x6c 0x0a 0x6c 0x09>;
						qcom,smem-state-names = "tx-enable", "tx-rings-empty";
						local-mac-address = [ a8 1b 5a 84 82 03 ];
					};
				};
			};
		};

		interrupt-controller@b000000 {
			compatible = "qcom,msm-qgic2";
			interrupt-controller;
			#interrupt-cells = <0x03>;
			reg = <0xb000000 0x1000 0xb002000 0x2000 0xb001000 0x1000 0xb004000 0x2000>;
			interrupts = <0x01 0x00 0xf04>;
			phandle = <0x01>;
		};

		mailbox@b011000 {
			compatible = "qcom,msm8916-apcs-kpss-global", "syscon";
			reg = <0xb011000 0x1000>;
			#mbox-cells = <0x01>;
			clocks = <0xa8 0x13 0x01>;
			clock-names = "pll", "aux";
			#clock-cells = <0x00>;
			phandle = <0x05>;
		};

		clock@b016000 {
			compatible = "qcom,msm8916-a53pll";
			reg = <0xb016000 0x40>;
			#clock-cells = <0x00>;
			clocks = <0x1b>;
			clock-names = "xo";
			phandle = <0xa8>;
		};

		timer@b020000 {
			#address-cells = <0x01>;
			#size-cells = <0x01>;
			ranges;
			compatible = "arm,armv7-timer-mem";
			reg = <0xb020000 0x1000>;
			clock-frequency = <0x124f800>;

			frame@b021000 {
				frame-number = <0x00>;
				interrupts = <0x00 0x08 0x04 0x00 0x07 0x04>;
				reg = <0xb021000 0x1000 0xb022000 0x1000>;
			};

			frame@b023000 {
				frame-number = <0x01>;
				interrupts = <0x00 0x09 0x04>;
				reg = <0xb023000 0x1000>;
				status = "disabled";
			};

			frame@b024000 {
				frame-number = <0x02>;
				interrupts = <0x00 0x0a 0x04>;
				reg = <0xb024000 0x1000>;
				status = "disabled";
			};

			frame@b025000 {
				frame-number = <0x03>;
				interrupts = <0x00 0x0b 0x04>;
				reg = <0xb025000 0x1000>;
				status = "disabled";
			};

			frame@b026000 {
				frame-number = <0x04>;
				interrupts = <0x00 0x0c 0x04>;
				reg = <0xb026000 0x1000>;
				status = "disabled";
			};

			frame@b027000 {
				frame-number = <0x05>;
				interrupts = <0x00 0x0d 0x04>;
				reg = <0xb027000 0x1000>;
				status = "disabled";
			};

			frame@b028000 {
				frame-number = <0x06>;
				interrupts = <0x00 0x0e 0x04>;
				reg = <0xb028000 0x1000>;
				status = "disabled";
			};
		};

		power-manager@b088000 {
			compatible = "qcom,msm8916-acc";
			reg = <0xb088000 0x1000>;
			status = "reserved";
			phandle = <0x08>;
		};

		power-manager@b089000 {
			compatible = "qcom,msm8916-saw2-v3.0-cpu", "qcom,saw2";
			reg = <0xb089000 0x1000>;
			status = "reserved";
			phandle = <0x09>;
		};

		power-manager@b098000 {
			compatible = "qcom,msm8916-acc";
			reg = <0xb098000 0x1000>;
			status = "reserved";
			phandle = <0x0b>;
		};

		power-manager@b099000 {
			compatible = "qcom,msm8916-saw2-v3.0-cpu", "qcom,saw2";
			reg = <0xb099000 0x1000>;
			status = "reserved";
			phandle = <0x0c>;
		};

		power-manager@b0a8000 {
			compatible = "qcom,msm8916-acc";
			reg = <0xb0a8000 0x1000>;
			status = "reserved";
			phandle = <0x0e>;
		};

		power-manager@b0a9000 {
			compatible = "qcom,msm8916-saw2-v3.0-cpu", "qcom,saw2";
			reg = <0xb0a9000 0x1000>;
			status = "reserved";
			phandle = <0x0f>;
		};

		power-manager@b0b8000 {
			compatible = "qcom,msm8916-acc";
			reg = <0xb0b8000 0x1000>;
			status = "reserved";
			phandle = <0x11>;
		};

		power-manager@b0b9000 {
			compatible = "qcom,msm8916-saw2-v3.0-cpu", "qcom,saw2";
			reg = <0xb0b9000 0x1000>;
			status = "reserved";
			phandle = <0x12>;
		};
	};

	thermal-zones {

		cpu0-1-thermal {
			polling-delay-passive = <0xfa>;
			thermal-sensors = <0xa9 0x05>;

			trips {

				trip-point0 {
					temperature = <0x124f8>;
					hysteresis = <0x7d0>;
					type = "passive";
					phandle = <0xaa>;
				};

				cpu-crit {
					temperature = <0x1adb0>;
					hysteresis = <0x7d0>;
					type = "critical";
				};
			};

			cooling-maps {

				map0 {
					trip = <0xaa>;
					cooling-device = <0x3d 0xffffffff 0xffffffff 0x3e 0xffffffff 0xffffffff 0x3f 0xffffffff 0xffffffff 0x40 0xffffffff 0xffffffff>;
				};
			};
		};

		cpu2-3-thermal {
			polling-delay-passive = <0xfa>;
			thermal-sensors = <0xa9 0x04>;

			trips {

				trip-point0 {
					temperature = <0x124f8>;
					hysteresis = <0x7d0>;
					type = "passive";
					phandle = <0xab>;
				};

				cpu-crit {
					temperature = <0x1adb0>;
					hysteresis = <0x7d0>;
					type = "critical";
				};
			};

			cooling-maps {

				map0 {
					trip = <0xab>;
					cooling-device = <0x3d 0xffffffff 0xffffffff 0x3e 0xffffffff 0xffffffff 0x3f 0xffffffff 0xffffffff 0x40 0xffffffff 0xffffffff>;
				};
			};
		};

		gpu-thermal {
			polling-delay-passive = <0xfa>;
			thermal-sensors = <0xa9 0x02>;

			cooling-maps {

				map0 {
					trip = <0xac>;
					cooling-device = <0xad 0xffffffff 0xffffffff>;
				};
			};

			trips {

				trip-point0 {
					temperature = <0x124f8>;
					hysteresis = <0x7d0>;
					type = "passive";
					phandle = <0xac>;
				};

				gpu-crit {
					temperature = <0x17318>;
					hysteresis = <0x7d0>;
					type = "critical";
				};
			};
		};

		camera-thermal {
			polling-delay-passive = <0xfa>;
			thermal-sensors = <0xa9 0x01>;

			trips {

				trip-point0 {
					temperature = <0x124f8>;
					hysteresis = <0x7d0>;
					type = "hot";
				};
			};
		};

		modem-thermal {
			polling-delay-passive = <0xfa>;
			thermal-sensors = <0xa9 0x00>;

			trips {

				trip-point0 {
					temperature = <0x14c08>;
					hysteresis = <0x7d0>;
					type = "hot";
				};
			};
		};

		pm8916-thermal {
			polling-delay-passive = <0x64>;
			thermal-sensors = <0xae>;

			trips {

				trip0 {
					temperature = <0x19a28>;
					hysteresis = <0x00>;
					type = "passive";
				};

				trip1 {
					temperature = <0x1e848>;
					hysteresis = <0x00>;
					type = "hot";
				};

				trip2 {
					temperature = <0x23668>;
					hysteresis = <0x00>;
					type = "critical";
				};
			};
		};
	};

	timer {
		compatible = "arm,armv8-timer";
		interrupts = <0x01 0x02 0xf08 0x01 0x03 0xf08 0x01 0x04 0xf08 0x01 0x01 0xf08>;
	};

	aliases {
		mmc0 = "/soc@0/mmc@7824900";
		mmc1 = "/soc@0/mmc@7864900";
		serial0 = "/soc@0/serial@78b0000";
	};

	battery {
		compatible = "simple-battery";
		voltage-min-design-microvolt = <0x33e140>;
		voltage-max-design-microvolt = <0x432380>;
		charge-full-design-microamp-hours = <0x275e20>;
		ocv-capacity-celsius = <0x19>;
		ocv-capacity-table-0 = <0x41fe88 0x64 0x418188 0x5f 0x40dd78 0x5a 0x400a88 0x55 0x3f2410 0x50 0x3e4180 0x4b 0x3d89e8 0x46 0x3cc2b0 0x41 0x3c2288 0x3c 0x3b43e0 0x37 0x3ad680 0x32 0x3a6d08 0x2d 0x3a2e88 0x28 0x39ec20 0x23 0x39a9b8 0x1e 0x396750 0x19 0x391d18 0x14 0x38cb10 0x10 0x387cf0 0x0d 0x386968 0x0b 0x385db0 0x0a 0x3859c8 0x09 0x3851f8 0x08 0x384a28 0x07 0x383a88 0x06 0x37fff0 0x05 0x370208 0x04 0x365240 0x03 0x357f50 0x02 0x32c030 0x01 0x2dc6c0 0x00>;
		phandle = <0x5d>;
	};

	gpio-keys {
		compatible = "gpio-keys";
		pinctrl-names = "default";
		pinctrl-0 = <0xaf>;
		label = "GPIO Buttons";

		button-volume-up {
			label = "Volume Up";
			gpios = <0x49 0x6b 0x01>;
			linux,code = <0x73>;
		};

		button-volume-down {
			label = "Volume Down";
			gpios = <0x49 0x6c 0x01>;
			linux,code = <0x72>;
		};
	};

	regulator-spk-boost {
		compatible = "regulator-fixed";
		regulator-name = "spk_boost";
		regulator-min-microvolt = <0x4c4b40>;
		regulator-max-microvolt = <0x4c4b40>;
		gpios = <0x49 0x76 0x00>;
		enable-active-high;
		regulator-always-on;
		regulator-boot-on;
		phandle = <0xb4>;
	};

	audio-amplifier {
		compatible = "simple-audio-amplifier";
		enable-gpios = <0x49 0x78 0x00>;
		VCC-supply = <0xb4>;
		sound-name-prefix = "Speaker Amp";
		phandle = <0xb3>;
	};

	regulator-panel-vdd {
		compatible = "regulator-fixed";
		regulator-name = "panel_vdd";
		regulator-min-microvolt = <0x2ab980>;
		regulator-max-microvolt = <0x2ab980>;
		gpio = <0x49 0x61 0x00>;
		enable-active-high;
		pinctrl-names = "default";
		pinctrl-0 = <0xb0>;
		phandle = <0x56>;
	};

	regulator-bl-vdd {
		compatible = "regulator-fixed";
		regulator-name = "bl_vdd";
		regulator-min-microvolt = <0x325aa0>;
		regulator-max-microvolt = <0x325aa0>;
		gpio = <0x49 0x62 0x00>;
		enable-active-high;
		regulator-always-on;
		regulator-boot-on;
		pinctrl-names = "default";
		pinctrl-0 = <0xb1>;
	};

	regulator-sd-vdd {
		compatible = "regulator-fixed";
		regulator-name = "sd_vdd";
		regulator-min-microvolt = <0x2d0370>;
		regulator-max-microvolt = <0x2d0370>;
		gpio = <0x49 0x74 0x00>;
		enable-active-high;
		startup-delay-us = <0xc8>;
		pinctrl-names = "default";
		pinctrl-0 = <0xb2>;
		phandle = <0x7c>;
	};

	dummy_extcon {
		compatible = "linux,extcon-usb-gpio";
		vbus-gpios = <0x49 0x71 0x00>;
		phandle = <0xa0>;
	};
};
